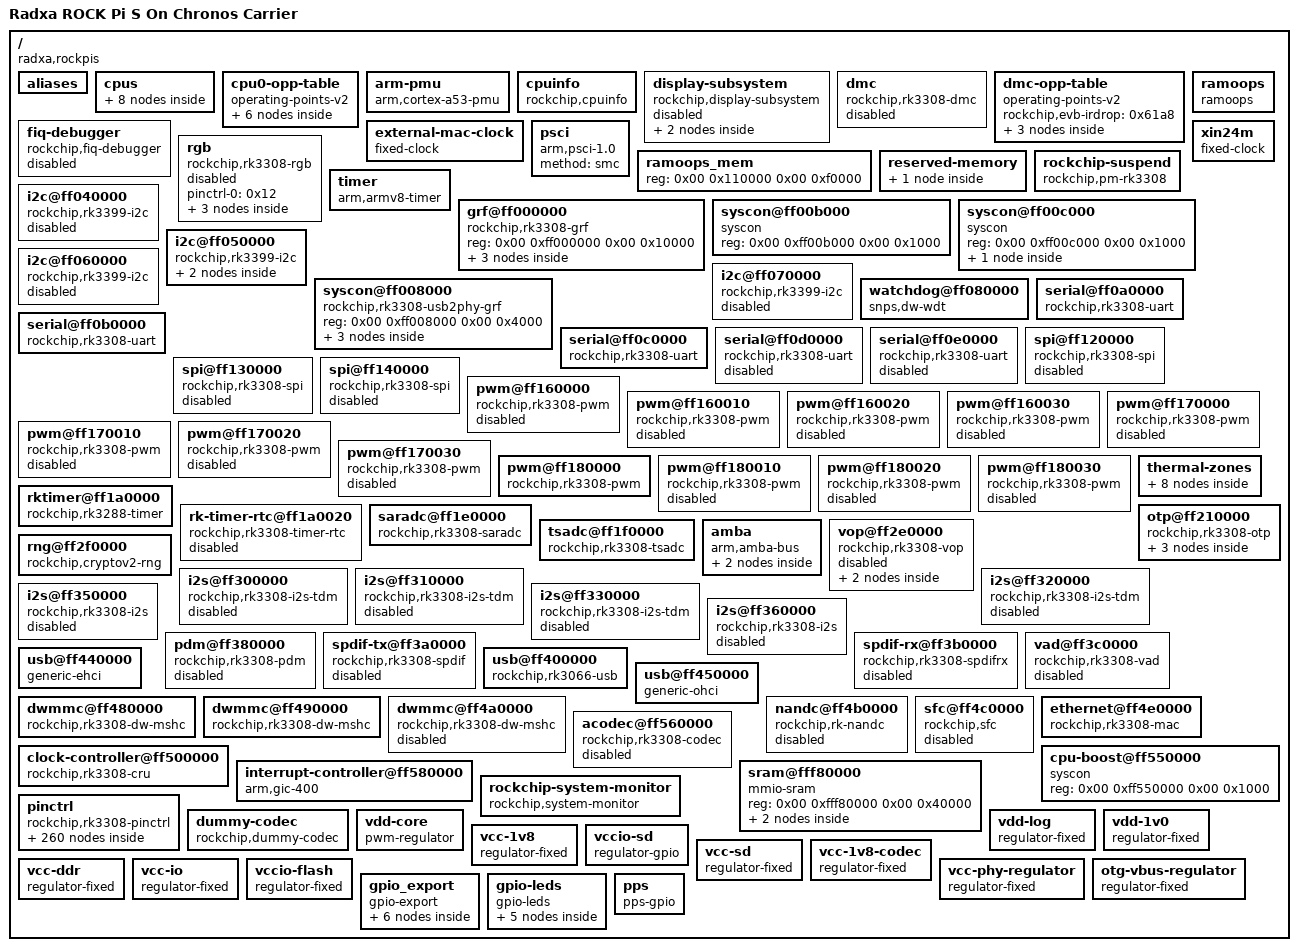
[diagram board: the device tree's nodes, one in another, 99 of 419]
/dts-v1/;

/ {
	compatible = "radxa,rockpis", "rockchip,rk3308";
	interrupt-parent = <0x01>;
	#address-cells = <0x02>;
	#size-cells = <0x02>;
	model = "Radxa ROCK Pi S On Chronos Carrier";

	aliases {
		ethernet0 = "/ethernet@ff4e0000";
		i2c0 = "/i2c@ff040000";
		i2c1 = "/i2c@ff050000";
		i2c2 = "/i2c@ff060000";
		i2c3 = "/i2c@ff070000";
		serial0 = "/serial@ff0a0000";
		serial1 = "/serial@ff0b0000";
		serial2 = "/serial@ff0c0000";
		serial3 = "/serial@ff0d0000";
		serial4 = "/serial@ff0e0000";
		spi0 = "/spi@ff120000";
		spi1 = "/spi@ff130000";
		spi2 = "/spi@ff140000";
	};

	cpus {
		#address-cells = <0x02>;
		#size-cells = <0x00>;

		cpu@0 {
			device_type = "cpu";
			compatible = "arm,cortex-a35", "arm,armv8";
			reg = <0x00 0x00>;
			enable-method = "psci";
			clocks = <0x02 0x05>;
			#cooling-cells = <0x02>;
			dynamic-power-coefficient = <0x53>;
			operating-points-v2 = <0x03>;
			cpu-idle-states = <0x04>;
			next-level-cache = <0x05>;
			cpu-supply = <0x06>;
			phandle = <0x08>;

			power-model {
				compatible = "simple-power-model";
				leakage-range = <0x05 0x32>;
				ls = <0x17c6 0x18ca 0xffffffc1>;
				static-coefficient = <0x186a0>;
				ts = <0xfffe55b6 0x18c54 0xfffff9ac 0x1e>;
				thermal-zone = "soc-thermal";
			};
		};

		cpu@1 {
			device_type = "cpu";
			compatible = "arm,cortex-a35", "arm,armv8";
			reg = <0x00 0x01>;
			enable-method = "psci";
			operating-points-v2 = <0x03>;
			cpu-idle-states = <0x04>;
			next-level-cache = <0x05>;
			phandle = <0x09>;
		};

		cpu@2 {
			device_type = "cpu";
			compatible = "arm,cortex-a35", "arm,armv8";
			reg = <0x00 0x02>;
			enable-method = "psci";
			operating-points-v2 = <0x03>;
			cpu-idle-states = <0x04>;
			next-level-cache = <0x05>;
			phandle = <0x0a>;
		};

		cpu@3 {
			device_type = "cpu";
			compatible = "arm,cortex-a35", "arm,armv8";
			reg = <0x00 0x03>;
			enable-method = "psci";
			operating-points-v2 = <0x03>;
			cpu-idle-states = <0x04>;
			next-level-cache = <0x05>;
			phandle = <0x0b>;
		};

		idle-states {
			entry-method = "psci";

			cpu-sleep {
				compatible = "arm,idle-state";
				local-timer-stop;
				arm,psci-suspend-param = <0x10000>;
				entry-latency-us = <0x78>;
				exit-latency-us = <0xfa>;
				min-residency-us = <0x384>;
				phandle = <0x04>;
			};
		};

		l2-cache {
			compatible = "cache";
			phandle = <0x05>;
		};
	};

	cpu0-opp-table {
		compatible = "operating-points-v2";
		opp-shared;
		rockchip,temp-hysteresis = <0x1388>;
		rockchip,low-temp = <0x00>;
		rockchip,low-temp-min-volt = <0xf4240>;
		rockchip,max-volt = <0x147260>;
		rockchip,low-temp-adjust-volt = <0x00 0x510 0xc350>;
		rockchip,evb-irdrop = <0x61a8>;
		nvmem-cells = <0x07>;
		nvmem-cell-names = "leakage";
		rockchip,pvtm-voltage-sel = <0x00 0xd2f0 0x00 0xd2f1 0xdac0 0x01 0xdac1 0xe484 0x02 0xe485 0xee48 0x03 0xee49 0xf80c 0x04 0xf80d 0x1869f 0x05>;
		rockchip,pvtm-freq = <0x639c0>;
		rockchip,pvtm-volt = <0xfa3e8>;
		rockchip,pvtm-ch = <0x00 0x00>;
		rockchip,pvtm-sample-time = <0x3e8>;
		rockchip,pvtm-number = <0x0a>;
		rockchip,pvtm-error = <0x3e8>;
		rockchip,pvtm-ref-temp = <0x23>;
		rockchip,pvtm-temp-prop = <0xfffffff1 0xffffffdb>;
		rockchip,thermal-zone = "soc-thermal";
		phandle = <0x03>;

		opp-408000000 {
			opp-hz = <0x00 0x18519600>;
			opp-microvolt = <0xe7ef0 0xe7ef0 0x147260>;
			clock-latency-ns = <0x9c40>;
			opp-suspend;
		};

		opp-600000000 {
			opp-hz = <0x00 0x23c34600>;
			opp-microvolt = <0xe7ef0 0xe7ef0 0x147260>;
			clock-latency-ns = <0x9c40>;
		};

		opp-816000000 {
			opp-hz = <0x00 0x30a32c00>;
			opp-microvolt = <0xfa3e8 0xfa3e8 0x147260>;
			opp-microvolt-L0 = <0xfa3e8 0xfa3e8 0x147260>;
			opp-microvolt-L1 = <0xfa3e8 0xfa3e8 0x147260>;
			opp-microvolt-L2 = <0xfa3e8 0xfa3e8 0x147260>;
			opp-microvolt-L3 = <0xf4240 0xf4240 0x147260>;
			opp-microvolt-L4 = <0xee098 0xee098 0x147260>;
			opp-microvolt-L5 = <0xe7ef0 0xe7ef0 0x147260>;
			clock-latency-ns = <0x9c40>;
		};

		opp-1008000000 {
			opp-hz = <0x00 0x3c14dc00>;
			opp-microvolt = <0x112a88 0x112a88 0x147260>;
			opp-microvolt-L0 = <0x112a88 0x112a88 0x147260>;
			opp-microvolt-L1 = <0x10c8e0 0x10c8e0 0x147260>;
			opp-microvolt-L2 = <0x10c8e0 0x10c8e0 0x147260>;
			opp-microvolt-L3 = <0x106738 0x106738 0x147260>;
			opp-microvolt-L4 = <0x100590 0x100590 0x147260>;
			opp-microvolt-L5 = <0xfa3e8 0xfa3e8 0x147260>;
			clock-latency-ns = <0x9c40>;
		};

		opp-1200000000 {
			opp-hz = <0x00 0x47868c00>;
			opp-microvolt = <0x1312d0 0x1312d0 0x147260>;
			opp-microvolt-L0 = <0x1312d0 0x1312d0 0x147260>;
			opp-microvolt-L1 = <0x12b128 0x12b128 0x147260>;
			opp-microvolt-L2 = <0x124f80 0x124f80 0x147260>;
			opp-microvolt-L3 = <0x11edd8 0x11edd8 0x147260>;
			opp-microvolt-L4 = <0x118c30 0x118c30 0x147260>;
			opp-microvolt-L5 = <0x112a88 0x112a88 0x147260>;
			clock-latency-ns = <0x9c40>;
		};

		opp-1296000000 {
			opp-hz = <0x00 0x4d3f6400>;
			opp-microvolt = <0x13d620 0x13d620 0x147260>;
			opp-microvolt-L0 = <0x13d620 0x13d620 0x147260>;
			opp-microvolt-L1 = <0x137478 0x137478 0x147260>;
			opp-microvolt-L2 = <0x1312d0 0x1312d0 0x147260>;
			opp-microvolt-L3 = <0x12b128 0x12b128 0x147260>;
			opp-microvolt-L4 = <0x124f80 0x124f80 0x147260>;
			opp-microvolt-L5 = <0x11edd8 0x11edd8 0x147260>;
			clock-latency-ns = <0x9c40>;
		};
	};

	arm-pmu {
		compatible = "arm,cortex-a53-pmu";
		interrupts = <0x00 0x53 0x04 0x00 0x54 0x04 0x00 0x55 0x04 0x00 0x56 0x04>;
		interrupt-affinity = <0x08 0x09 0x0a 0x0b>;
	};

	cpuinfo {
		compatible = "rockchip,cpuinfo";
		nvmem-cells = <0x0c>;
		nvmem-cell-names = "id";
	};

	display-subsystem {
		compatible = "rockchip,display-subsystem";
		ports = <0x0d>;
		logo-memory-region = <0x0e>;
		status = "disabled";
		phandle = <0x87>;

		route {

			route-rgb {
				status = "disabled";
				logo,uboot = "logo.bmp";
				logo,mode = "center";
				charge_logo,mode = "center";
				connect = <0x0f>;
				phandle = <0x88>;
			};
		};
	};

	dmc {
		compatible = "rockchip,rk3308-dmc";
		clocks = <0x02 0x46>;
		clock-names = "dmc_clk";
		operating-points-v2 = <0x10>;
		status = "disabled";
		phandle = <0x89>;
	};

	dmc-opp-table {
		compatible = "operating-points-v2";
		rockchip,evb-irdrop = <0x61a8>;
		phandle = <0x10>;

		opp-394000000 {
			opp-hz = <0x00 0x177bf680>;
			opp-microvolt = <0xe7ef0>;
		};

		opp-452000000 {
			opp-hz = <0x00 0x1af0f900>;
			opp-microvolt = <0xee098>;
		};

		opp-590000000 {
			opp-hz = <0x00 0x232aaf80>;
			opp-microvolt = <0xf4240>;
		};
	};

	fiq-debugger {
		compatible = "rockchip,fiq-debugger";
		rockchip,serial-id = <0x02>;
		rockchip,wake-irq = <0x00>;
		rockchip,irq-mode-enable = <0x00>;
		rockchip,baudrate = <0x16e360>;
		interrupts = <0x00 0x74 0x04>;
		status = "disabled";
		phandle = <0x8a>;
	};

	external-mac-clock {
		compatible = "fixed-clock";
		clock-frequency = <0x2faf080>;
		clock-output-names = "mac_clkin";
		#clock-cells = <0x00>;
		phandle = <0x8b>;
	};

	psci {
		compatible = "arm,psci-1.0";
		method = "smc";
	};

	ramoops_mem {
		reg = <0x00 0x110000 0x00 0xf0000>;
		reg-names = "ramoops_mem";
		phandle = <0x11>;
	};

	ramoops {
		compatible = "ramoops";
		record-size = <0x00 0x30000>;
		console-size = <0x00 0xc0000>;
		ftrace-size = <0x00 0x00>;
		pmsg-size = <0x00 0x00>;
		memory-region = <0x11>;
		phandle = <0x8c>;
	};

	rgb {
		compatible = "rockchip,rk3308-rgb";
		status = "disabled";
		pinctrl-names = "default";
		pinctrl-0 = <0x12>;
		phandle = <0x8d>;

		ports {
			#address-cells = <0x01>;
			#size-cells = <0x00>;

			port@0 {
				reg = <0x00>;
				#address-cells = <0x01>;
				#size-cells = <0x00>;

				endpoint@0 {
					reg = <0x00>;
					remote-endpoint = <0x0f>;
					phandle = <0x4d>;
				};
			};
		};
	};

	reserved-memory {
		#address-cells = <0x02>;
		#size-cells = <0x02>;
		ranges;

		drm-logo@00000000 {
			compatible = "rockchip,drm-logo";
			reg = <0x00 0x00 0x00 0x00>;
			phandle = <0x0e>;
		};
	};

	rockchip-suspend {
		compatible = "rockchip,pm-rk3308";
		status = "okay";
		rockchip,sleep-mode-config = <0x8000008>;
		rockchip,wakeup-config = <0x40000>;
		rockchip,pwm-regulator-config = <0x04>;
		phandle = <0x8e>;
	};

	timer {
		compatible = "arm,armv8-timer";
		interrupts = <0x01 0x0d 0xf04 0x01 0x0e 0xf04 0x01 0x0b 0xf04 0x01 0x0a 0xf04>;
	};

	xin24m {
		compatible = "fixed-clock";
		#clock-cells = <0x00>;
		clock-frequency = <0x16e3600>;
		clock-output-names = "xin24m";
		phandle = <0x8f>;
	};

	grf@ff000000 {
		compatible = "rockchip,rk3308-grf", "syscon", "simple-mfd";
		reg = <0x00 0xff000000 0x00 0x10000>;
		phandle = <0x4a>;

		io-domains {
			compatible = "rockchip,rk3308-io-voltage-domain";
			status = "okay";
			vccio0-supply = <0x13>;
			vccio1-supply = <0x13>;
			vccio2-supply = <0x14>;
			vccio3-supply = <0x15>;
			vccio4-supply = <0x14>;
			vccio5-supply = <0x13>;
			phandle = <0x90>;
		};

		pmu-pvtm {
			compatible = "rockchip,rk3308-pmu-pvtm";
			clocks = <0x02 0x4a>;
			clock-names = "pmu";
			phandle = <0x91>;
		};

		reboot-mode {
			compatible = "syscon-reboot-mode";
			offset = <0x500>;
			mode-bootloader = <0x5242c301>;
			mode-loader = <0x5242c301>;
			mode-normal = <0x5242c300>;
			mode-recovery = <0x5242c303>;
			mode-fastboot = <0x5242c309>;
			mode-panic = <0x5242c307>;
			mode-watchdog = <0x5242c308>;
		};
	};

	syscon@ff00b000 {
		compatible = "syscon", "simple-mfd";
		reg = <0x00 0xff00b000 0x00 0x1000>;
		#address-cells = <0x01>;
		#size-cells = <0x01>;
		phandle = <0x76>;
	};

	syscon@ff00c000 {
		compatible = "syscon", "simple-mfd";
		reg = <0x00 0xff00c000 0x00 0x1000>;
		#address-cells = <0x01>;
		#size-cells = <0x01>;
		phandle = <0x92>;

		pvtm {
			compatible = "rockchip,rk3308-pvtm";
			clocks = <0x02 0x10>;
			clock-names = "core";
			phandle = <0x93>;
		};
	};

	i2c@ff040000 {
		compatible = "rockchip,rk3399-i2c";
		reg = <0x00 0xff040000 0x00 0x1000>;
		clocks = <0x02 0x16 0x02 0xca>;
		clock-names = "i2c", "pclk";
		interrupts = <0x00 0x0b 0x04>;
		pinctrl-names = "default";
		pinctrl-0 = <0x16>;
		#address-cells = <0x01>;
		#size-cells = <0x00>;
		status = "disabled";
		phandle = <0x94>;
	};

	i2c@ff050000 {
		compatible = "rockchip,rk3399-i2c";
		reg = <0x00 0xff050000 0x00 0x1000>;
		clocks = <0x02 0x17 0x02 0xcb>;
		clock-names = "i2c", "pclk";
		interrupts = <0x00 0x0c 0x04>;
		pinctrl-names = "default";
		pinctrl-0 = <0x17>;
		#address-cells = <0x01>;
		#size-cells = <0x00>;
		status = "okay";
		clock-frequency = <0x61a80>;
		phandle = <0x95>;

		hym8563@51 {
			compatible = "haoyu,hym8563";
			reg = <0x51>;
			#clock-cells = <0x00>;
			clock-frequency = <0x8000>;
			clock-output-names = "xin32k";
			pinctrl-names = "default";
			pinctrl-0 = <0x18>;
			interrupt-parent = <0x19>;
			interrupts = <0x11 0x08>;
			status = "okay";
			phandle = <0x96>;
		};

		eeprom@54 {
			compatible = "st,24c64";
			reg = <0x54>;
			pagesize = <0x20>;
			phandle = <0x97>;
		};
	};

	i2c@ff060000 {
		compatible = "rockchip,rk3399-i2c";
		reg = <0x00 0xff060000 0x00 0x1000>;
		clocks = <0x02 0x18 0x02 0xcc>;
		clock-names = "i2c", "pclk";
		interrupts = <0x00 0x0d 0x04>;
		pinctrl-names = "default";
		pinctrl-0 = <0x1a>;
		#address-cells = <0x01>;
		#size-cells = <0x00>;
		status = "disabled";
		phandle = <0x98>;
	};

	i2c@ff070000 {
		compatible = "rockchip,rk3399-i2c";
		reg = <0x00 0xff070000 0x00 0x1000>;
		clocks = <0x02 0x19 0x02 0xcd>;
		clock-names = "i2c", "pclk";
		interrupts = <0x00 0x0e 0x04>;
		pinctrl-names = "default";
		pinctrl-0 = <0x1b>;
		#address-cells = <0x01>;
		#size-cells = <0x00>;
		status = "disabled";
		phandle = <0x99>;
	};

	syscon@ff008000 {
		compatible = "rockchip,rk3308-usb2phy-grf", "syscon", "simple-mfd";
		reg = <0x00 0xff008000 0x00 0x4000>;
		#address-cells = <0x01>;
		#size-cells = <0x01>;
		phandle = <0x9a>;

		usb2-phy@100 {
			compatible = "rockchip,rk3308-usb2phy";
			reg = <0x100 0x10>;
			clocks = <0x02 0x48>;
			clock-names = "phyclk";
			#clock-cells = <0x00>;
			assigned-clocks = <0x02 0x0e>;
			assigned-clock-parents = <0x1c>;
			clock-output-names = "usb480m_phy";
			status = "okay";
			phandle = <0x1c>;

			otg-port {
				#phy-cells = <0x00>;
				interrupts = <0x00 0x43 0x04 0x00 0x44 0x04 0x00 0x45 0x04>;
				interrupt-names = "otg-bvalid", "otg-id", "linestate";
				status = "okay";
				vbus-supply = <0x1d>;
				phandle = <0x67>;
			};

			host-port {
				#phy-cells = <0x00>;
				interrupts = <0x00 0x4a 0x04>;
				interrupt-names = "linestate";
				status = "okay";
				phy-supply = <0x1d>;
				phandle = <0x68>;
			};
		};
	};

	watchdog@ff080000 {
		compatible = "snps,dw-wdt";
		reg = <0x00 0xff080000 0x00 0x100>;
		clocks = <0x02 0xd6>;
		interrupts = <0x00 0x0a 0x04>;
		status = "okay";
		phandle = <0x9b>;
	};

	serial@ff0a0000 {
		compatible = "rockchip,rk3308-uart", "snps,dw-apb-uart";
		reg = <0x00 0xff0a0000 0x00 0x100>;
		interrupts = <0x00 0x12 0x04>;
		clocks = <0x02 0x11 0x02 0xc5>;
		clock-names = "baudclk", "apb_pclk";
		reg-shift = <0x02>;
		reg-io-width = <0x04>;
		dmas = <0x1e 0x04 0x1e 0x05>;
		dma-names = "tx", "rx";
		pinctrl-names = "default";
		pinctrl-0 = <0x1f>;
		status = "okay";
		phandle = <0x9c>;
	};

	serial@ff0b0000 {
		compatible = "rockchip,rk3308-uart", "snps,dw-apb-uart";
		reg = <0x00 0xff0b0000 0x00 0x100>;
		interrupts = <0x00 0x13 0x04>;
		clocks = <0x02 0x12 0x02 0xc6>;
		clock-names = "baudclk", "apb_pclk";
		reg-shift = <0x02>;
		reg-io-width = <0x04>;
		dmas = <0x1e 0x06 0x1e 0x07>;
		dma-names = "tx", "rx";
		pinctrl-names = "default";
		pinctrl-0 = <0x20>;
		status = "okay";
		phandle = <0x9d>;
	};

	serial@ff0c0000 {
		compatible = "rockchip,rk3308-uart", "snps,dw-apb-uart";
		reg = <0x00 0xff0c0000 0x00 0x100>;
		interrupts = <0x00 0x14 0x04>;
		clocks = <0x02 0x13 0x02 0xc7>;
		clock-names = "baudclk", "apb_pclk";
		reg-shift = <0x02>;
		reg-io-width = <0x04>;
		dmas = <0x1e 0x08 0x1e 0x09>;
		dma-names = "tx", "rx";
		pinctrl-names = "default";
		pinctrl-0 = <0x21>;
		status = "okay";
		phandle = <0x9e>;
	};

	serial@ff0d0000 {
		compatible = "rockchip,rk3308-uart", "snps,dw-apb-uart";
		reg = <0x00 0xff0d0000 0x00 0x100>;
		interrupts = <0x00 0x15 0x04>;
		clocks = <0x02 0x14 0x02 0xc8>;
		clock-names = "baudclk", "apb_pclk";
		reg-shift = <0x02>;
		reg-io-width = <0x04>;
		dmas = <0x1e 0x0a 0x1e 0x0b>;
		dma-names = "tx", "rx";
		pinctrl-names = "default";
		pinctrl-0 = <0x22>;
		status = "disabled";
		phandle = <0x9f>;
	};

	serial@ff0e0000 {
		compatible = "rockchip,rk3308-uart", "snps,dw-apb-uart";
		reg = <0x00 0xff0e0000 0x00 0x100>;
		interrupts = <0x00 0x16 0x04>;
		clocks = <0x02 0x15 0x02 0xc9>;
		clock-names = "baudclk", "apb_pclk";
		reg-shift = <0x02>;
		reg-io-width = <0x04>;
		dmas = <0x23 0x12 0x23 0x13>;
		dma-names = "tx", "rx";
		pinctrl-names = "default";
		pinctrl-0 = <0x24 0x25 0x26>;
		status = "disabled";
		phandle = <0xa0>;
	};

	spi@ff120000 {
		compatible = "rockchip,rk3308-spi", "rockchip,rk3066-spi";
		reg = <0x00 0xff120000 0x00 0x1000>;
		interrupts = <0x00 0x0f 0x04>;
		#address-cells = <0x01>;
		#size-cells = <0x00>;
		clocks = <0x02 0x1b 0x02 0xcf>;
		clock-names = "spiclk", "apb_pclk";
		dmas = <0x1e 0x00 0x1e 0x01>;
		dma-names = "tx", "rx";
		pinctrl-names = "default", "high_speed";
		pinctrl-0 = <0x27 0x28 0x29 0x2a>;
		pinctrl-1 = <0x2b 0x28 0x2c 0x2d>;
		status = "disabled";
		phandle = <0xa1>;
	};

	spi@ff130000 {
		compatible = "rockchip,rk3308-spi", "rockchip,rk3066-spi";
		reg = <0x00 0xff130000 0x00 0x1000>;
		interrupts = <0x00 0x10 0x04>;
		#address-cells = <0x01>;
		#size-cells = <0x00>;
		clocks = <0x02 0x1c 0x02 0xd0>;
		clock-names = "spiclk", "apb_pclk";
		dmas = <0x1e 0x02 0x1e 0x03>;
		dma-names = "tx", "rx";
		pinctrl-names = "default", "high_speed";
		pinctrl-0 = <0x2e 0x2f 0x30 0x31>;
		pinctrl-1 = <0x32 0x2f 0x33 0x34>;
		status = "disabled";
		phandle = <0xa2>;
	};

	spi@ff140000 {
		compatible = "rockchip,rk3308-spi", "rockchip,rk3066-spi";
		reg = <0x00 0xff140000 0x00 0x1000>;
		interrupts = <0x00 0x11 0x04>;
		#address-cells = <0x01>;
		#size-cells = <0x00>;
		clocks = <0x02 0x1d 0x02 0xd1>;
		clock-names = "spiclk", "apb_pclk";
		dmas = <0x23 0x10 0x23 0x11>;
		dma-names = "tx", "rx";
		pinctrl-names = "default", "high_speed";
		pinctrl-0 = <0x35 0x36 0x37 0x38>;
		pinctrl-1 = <0x39 0x36 0x3a 0x3b>;
		status = "disabled";
		phandle = <0xa3>;
	};

	pwm@ff160000 {
		compatible = "rockchip,rk3308-pwm", "rockchip,rk3328-pwm";
		reg = <0x00 0xff160000 0x00 0x10>;
		#pwm-cells = <0x03>;
		pinctrl-names = "active";
		pinctrl-0 = <0x3c>;
		clocks = <0x02 0x79 0x02 0xe8>;
		clock-names = "pwm", "pclk";
		status = "disabled";
		phandle = <0xa4>;
	};

	pwm@ff160010 {
		compatible = "rockchip,rk3308-pwm", "rockchip,rk3328-pwm";
		reg = <0x00 0xff160010 0x00 0x10>;
		#pwm-cells = <0x03>;
		pinctrl-names = "active";
		pinctrl-0 = <0x3d>;
		clocks = <0x02 0x79 0x02 0xe8>;
		clock-names = "pwm", "pclk";
		status = "disabled";
		phandle = <0xa5>;
	};

	pwm@ff160020 {
		compatible = "rockchip,rk3308-pwm", "rockchip,rk3328-pwm";
		reg = <0x00 0xff160020 0x00 0x10>;
		#pwm-cells = <0x03>;
		pinctrl-names = "active";
		pinctrl-0 = <0x3e>;
		clocks = <0x02 0x79 0x02 0xe8>;
		clock-names = "pwm", "pclk";
		status = "disabled";
		phandle = <0xa6>;
	};

	pwm@ff160030 {
		compatible = "rockchip,rk3308-pwm", "rockchip,rk3328-pwm";
		reg = <0x00 0xff160030 0x00 0x10>;
		#pwm-cells = <0x03>;
		pinctrl-names = "active";
		pinctrl-0 = <0x3f>;
		clocks = <0x02 0x79 0x02 0xe8>;
		clock-names = "pwm", "pclk";
		status = "disabled";
		phandle = <0xa7>;
	};

	pwm@ff170000 {
		compatible = "rockchip,rk3308-pwm", "rockchip,rk3328-pwm";
		reg = <0x00 0xff170000 0x00 0x10>;
		#pwm-cells = <0x03>;
		pinctrl-names = "active";
		pinctrl-0 = <0x40>;
		clocks = <0x02 0x78 0x02 0xe7>;
		clock-names = "pwm", "pclk";
		status = "disabled";
		phandle = <0xa8>;
	};

	pwm@ff170010 {
		compatible = "rockchip,rk3308-pwm", "rockchip,rk3328-pwm";
		reg = <0x00 0xff170010 0x00 0x10>;
		#pwm-cells = <0x03>;
		pinctrl-names = "active";
		pinctrl-0 = <0x41>;
		clocks = <0x02 0x78 0x02 0xe7>;
		clock-names = "pwm", "pclk";
		status = "disabled";
		phandle = <0xa9>;
	};

	pwm@ff170020 {
		compatible = "rockchip,rk3308-pwm", "rockchip,rk3328-pwm";
		reg = <0x00 0xff170020 0x00 0x10>;
		#pwm-cells = <0x03>;
		pinctrl-names = "active";
		pinctrl-0 = <0x42>;
		clocks = <0x02 0x78 0x02 0xe7>;
		clock-names = "pwm", "pclk";
		status = "disabled";
		phandle = <0xaa>;
	};

	pwm@ff170030 {
		compatible = "rockchip,rk3308-pwm", "rockchip,rk3328-pwm";
		reg = <0x00 0xff170030 0x00 0x10>;
		#pwm-cells = <0x03>;
		pinctrl-names = "active";
		pinctrl-0 = <0x43>;
		clocks = <0x02 0x78 0x02 0xe7>;
		clock-names = "pwm", "pclk";
		status = "disabled";
		phandle = <0xab>;
	};

	pwm@ff180000 {
		compatible = "rockchip,rk3308-pwm", "rockchip,rk3328-pwm";
		reg = <0x00 0xff180000 0x00 0x10>;
		#pwm-cells = <0x03>;
		pinctrl-names = "active";
		pinctrl-0 = <0x44>;
		clocks = <0x02 0x1a 0x02 0xce>;
		clock-names = "pwm", "pclk";
		status = "okay";
		phandle = <0x82>;
	};

	pwm@ff180010 {
		compatible = "rockchip,rk3308-pwm", "rockchip,rk3328-pwm";
		reg = <0x00 0xff180010 0x00 0x10>;
		#pwm-cells = <0x03>;
		pinctrl-names = "active";
		pinctrl-0 = <0x45>;
		clocks = <0x02 0x1a 0x02 0xce>;
		clock-names = "pwm", "pclk";
		status = "disabled";
		phandle = <0xac>;
	};

	pwm@ff180020 {
		compatible = "rockchip,rk3308-pwm", "rockchip,rk3328-pwm";
		reg = <0x00 0xff180020 0x00 0x10>;
		#pwm-cells = <0x03>;
		pinctrl-names = "active";
		pinctrl-0 = <0x46>;
		clocks = <0x02 0x1a 0x02 0xce>;
		clock-names = "pwm", "pclk";
		status = "disabled";
		phandle = <0xad>;
	};

	pwm@ff180030 {
		compatible = "rockchip,rk3308-pwm", "rockchip,rk3328-pwm";
		reg = <0x00 0xff180030 0x00 0x10>;
		#pwm-cells = <0x03>;
		pinctrl-names = "active";
		pinctrl-0 = <0x47>;
		clocks = <0x02 0x1a 0x02 0xce>;
		clock-names = "pwm", "pclk";
		status = "disabled";
		phandle = <0xae>;
	};

	rktimer@ff1a0000 {
		compatible = "rockchip,rk3288-timer";
		reg = <0x00 0xff1a0000 0x00 0x20>;
		interrupts = <0x00 0x19 0x04>;
		clocks = <0x02 0xd4 0x02 0x1e>;
		clock-names = "pclk", "timer";
		phandle = <0xaf>;
	};

	rk-timer-rtc@ff1a0020 {
		compatible = "rockchip,rk3308-timer-rtc";
		reg = <0x00 0xff1a0020 0x00 0x20>;
		interrupts = <0x00 0x1a 0x04>;
		clocks = <0x02 0xd4 0x02 0x1f>;
		clock-names = "pclk", "timer";
		status = "disabled";
		phandle = <0xb0>;
	};

	saradc@ff1e0000 {
		compatible = "rockchip,rk3308-saradc", "rockchip,rk3399-saradc";
		reg = <0x00 0xff1e0000 0x00 0x100>;
		interrupts = <0x00 0x25 0x04>;
		#io-channel-cells = <0x01>;
		clocks = <0x02 0x25 0x02 0xd2>;
		clock-names = "saradc", "apb_pclk";
		resets = <0x02 0x46>;
		reset-names = "saradc-apb";
		status = "okay";
		phandle = <0xb1>;
	};

	thermal-zones {
		phandle = <0xb2>;

		soc-thermal {
			polling-delay-passive = <0x14>;
			polling-delay = <0x3e8>;
			sustainable-power = <0x168>;
			thermal-sensors = <0x48 0x01>;
			phandle = <0xb3>;

			trips {

				trip-point-0 {
					temperature = <0x11170>;
					hysteresis = <0x7d0>;
					type = "passive";
					phandle = <0xb4>;
				};

				trip-point-1 {
					temperature = <0x14c08>;
					hysteresis = <0x7d0>;
					type = "passive";
					phandle = <0x49>;
				};

				soc-crit {
					temperature = <0x1c138>;
					hysteresis = <0x7d0>;
					type = "critical";
					phandle = <0xb5>;
				};
			};

			cooling-maps {

				map0 {
					trip = <0x49>;
					cooling-device = <0x08 0xffffffff 0xffffffff>;
					contribution = <0x1000>;
				};
			};
		};

		logic-thermal {
			polling-delay-passive = <0x64>;
			polling-delay = <0x3e8>;
			thermal-sensors = <0x48 0x00>;
			phandle = <0xb6>;
		};
	};

	tsadc@ff1f0000 {
		compatible = "rockchip,rk3308-tsadc";
		reg = <0x00 0xff1f0000 0x00 0x100>;
		interrupts = <0x00 0x26 0x04>;
		rockchip,grf = <0x4a>;
		clocks = <0x02 0x24 0x02 0xd3>;
		clock-names = "tsadc", "apb_pclk";
		assigned-clocks = <0x02 0x24>;
		assigned-clock-rates = <0xc350>;
		resets = <0x02 0x48>;
		reset-names = "tsadc-apb";
		pinctrl-names = "gpio", "otpout";
		pinctrl-0 = <0x4b>;
		pinctrl-1 = <0x4c>;
		#thermal-sensor-cells = <0x01>;
		rockchip,hw-tshut-temp = <0x1d4c0>;
		status = "okay";
		rockchip,hw-tshut-mode = <0x00>;
		rockchip,hw-tshut-polarity = <0x01>;
		phandle = <0x48>;
	};

	otp@ff210000 {
		compatible = "rockchip,rk3308-otp";
		reg = <0x00 0xff210000 0x00 0x4000>;
		#address-cells = <0x01>;
		#size-cells = <0x01>;
		clocks = <0x02 0x27 0x02 0xd5 0x02 0xe5>;
		clock-names = "clk_otp", "pclk_otp", "pclk_otp_phy";
		resets = <0x02 0x54>;
		reset-names = "otp_phy";
		phandle = <0xb7>;

		id@7 {
			reg = <0x07 0x10>;
			phandle = <0x0c>;
		};

		cpu-leakage@17 {
			reg = <0x17 0x01>;
			phandle = <0x07>;
		};

		logic-leakage@18 {
			reg = <0x18 0x01>;
			phandle = <0xb8>;
		};
	};

	amba {
		compatible = "arm,amba-bus";
		#address-cells = <0x02>;
		#size-cells = <0x02>;
		ranges;

		dma-controller@ff2c0000 {
			compatible = "arm,pl330", "arm,primecell";
			reg = <0x00 0xff2c0000 0x00 0x4000>;
			interrupts = <0x00 0x00 0x04 0x00 0x01 0x04>;
			#dma-cells = <0x01>;
			clocks = <0x02 0x8a>;
			clock-names = "apb_pclk";
			peripherals-req-type-burst;
			phandle = <0x1e>;
		};

		dma-controller@ff2d0000 {
			compatible = "arm,pl330", "arm,primecell";
			reg = <0x00 0xff2d0000 0x00 0x4000>;
			interrupts = <0x00 0x02 0x04 0x00 0x03 0x04>;
			#dma-cells = <0x01>;
			clocks = <0x02 0x8b>;
			clock-names = "apb_pclk";
			peripherals-req-type-burst;
			phandle = <0x23>;
		};
	};

	vop@ff2e0000 {
		compatible = "rockchip,rk3308-vop";
		reg = <0x00 0xff2e0000 0x00 0x1fc 0x00 0xff2e0a00 0x00 0x400>;
		reg-names = "regs", "gamma_lut";
		interrupts = <0x00 0x2e 0x04>;
		clocks = <0x02 0x88 0x02 0x7d 0x02 0xac>;
		clock-names = "aclk_vop", "dclk_vop", "hclk_vop";
		status = "disabled";
		phandle = <0xb9>;

		port {
			#address-cells = <0x01>;
			#size-cells = <0x00>;
			phandle = <0x0d>;

			endpoint@0 {
				reg = <0x00>;
				remote-endpoint = <0x4d>;
				phandle = <0x0f>;
			};
		};
	};

	rng@ff2f0000 {
		compatible = "rockchip,cryptov2-rng";
		reg = <0x00 0xff2f0000 0x00 0x4000>;
		clocks = <0x02 0x29 0x02 0x2a 0x02 0x87 0x02 0xab>;
		clock-names = "clk_crypto", "clk_crypto_apk", "aclk_crypto", "hclk_crypto";
		assigned-clocks = <0x02 0x29 0x02 0x2a 0x02 0x87 0x02 0xab>;
		assigned-clock-rates = <0x8f0d180 0x8f0d180 0xbebc200 0x5f5e100>;
		resets = <0x02 0x24>;
		reset-names = "reset";
		status = "okay";
		phandle = <0xba>;
	};

	i2s@ff300000 {
		compatible = "rockchip,rk3308-i2s-tdm";
		reg = <0x00 0xff300000 0x00 0x1000>;
		interrupts = <0x00 0x30 0x04>;
		clocks = <0x02 0x4c 0x02 0x4e 0x02 0xa4 0x02 0x6e 0x02 0x6f 0x02 0x03 0x02 0x04>;
		clock-names = "mclk_tx", "mclk_rx", "hclk", "mclk_tx_src", "mclk_rx_src", "mclk_root0", "mclk_root1";
		dmas = <0x23 0x00 0x23 0x01>;
		dma-names = "tx", "rx";
		resets = <0x02 0x89 0x02 0x8a>;
		reset-names = "tx-m", "rx-m";
		rockchip,cru = <0x02>;
		rockchip,grf = <0x4a>;
		rockchip,mclk-calibrate;
		pinctrl-names = "default";
		pinctrl-0 = <0x4e 0x4f 0x50 0x51 0x52 0x53 0x54 0x55 0x56 0x57 0x58 0x59 0x5a>;
		status = "disabled";
		phandle = <0xbb>;
	};

	i2s@ff310000 {
		compatible = "rockchip,rk3308-i2s-tdm";
		reg = <0x00 0xff310000 0x00 0x1000>;
		interrupts = <0x00 0x31 0x04>;
		clocks = <0x02 0x50 0x02 0x52 0x02 0xa5 0x02 0x70 0x02 0x71 0x02 0x03 0x02 0x04>;
		clock-names = "mclk_tx", "mclk_rx", "hclk", "mclk_tx_src", "mclk_rx_src", "mclk_root0", "mclk_root1";
		dmas = <0x23 0x02 0x23 0x03>;
		dma-names = "tx", "rx";
		resets = <0x02 0x8c 0x02 0x8d>;
		reset-names = "tx-m", "rx-m";
		rockchip,cru = <0x02>;
		rockchip,grf = <0x4a>;
		rockchip,mclk-calibrate;
		rockchip,io-multiplex;
		status = "disabled";
		phandle = <0xbc>;
	};

	i2s@ff320000 {
		compatible = "rockchip,rk3308-i2s-tdm";
		reg = <0x00 0xff320000 0x00 0x1000>;
		interrupts = <0x00 0x32 0x04>;
		clocks = <0x02 0x54 0x02 0x56 0x02 0xa6 0x02 0x72 0x02 0x73 0x02 0x03 0x02 0x04>;
		clock-names = "mclk_tx", "mclk_rx", "hclk", "mclk_tx_src", "mclk_rx_src", "mclk_root0", "mclk_root1";
		dmas = <0x23 0x04 0x23 0x05>;
		dma-names = "tx", "rx";
		resets = <0x02 0x8f 0x02 0x90>;
		reset-names = "tx-m", "rx-m";
		rockchip,cru = <0x02>;
		rockchip,grf = <0x4a>;
		rockchip,mclk-calibrate;
		status = "disabled";
		phandle = <0xbd>;
	};

	i2s@ff330000 {
		compatible = "rockchip,rk3308-i2s-tdm";
		reg = <0x00 0xff330000 0x00 0x1000>;
		interrupts = <0x00 0x33 0x04>;
		clocks = <0x02 0x58 0x02 0x5a 0x02 0xa7 0x02 0x74 0x02 0x75 0x02 0x03 0x02 0x04>;
		clock-names = "mclk_tx", "mclk_rx", "hclk", "mclk_tx_src", "mclk_rx_src", "mclk_root0", "mclk_root1";
		dmas = <0x23 0x07>;
		dma-names = "rx";
		resets = <0x02 0x92 0x02 0x93>;
		reset-names = "tx-m", "rx-m";
		rockchip,cru = <0x02>;
		rockchip,grf = <0x4a>;
		rockchip,mclk-calibrate;
		status = "disabled";
		phandle = <0xbe>;
	};

	i2s@ff350000 {
		compatible = "rockchip,rk3308-i2s", "rockchip,rk3066-i2s";
		reg = <0x00 0xff350000 0x00 0x1000>;
		interrupts = <0x00 0x34 0x04>;
		clocks = <0x02 0x5c 0x02 0xa8>;
		clock-names = "i2s_clk", "i2s_hclk";
		dmas = <0x23 0x08 0x23 0x09>;
		dma-names = "tx", "rx";
		resets = <0x02 0x95 0x02 0x94>;
		reset-names = "reset-m", "reset-h";
		pinctrl-names = "default";
		pinctrl-0 = <0x5b 0x5c 0x5d 0x5e>;
		status = "disabled";
		phandle = <0xbf>;
	};

	i2s@ff360000 {
		compatible = "rockchip,rk3308-i2s", "rockchip,rk3066-i2s";
		reg = <0x00 0xff360000 0x00 0x1000>;
		interrupts = <0x00 0x35 0x04>;
		clocks = <0x02 0x5e 0x02 0xa9>;
		clock-names = "i2s_clk", "i2s_hclk";
		dmas = <0x23 0x0b>;
		dma-names = "rx";
		resets = <0x02 0x97 0x02 0x96>;
		reset-names = "reset-m", "reset-h";
		status = "disabled";
		phandle = <0xc0>;
	};

	pdm@ff380000 {
		compatible = "rockchip,rk3308-pdm", "rockchip,pdm";
		reg = <0x00 0xff380000 0x00 0x1000>;
		clocks = <0x02 0x4b 0x02 0xa1>;
		clock-names = "pdm_clk", "pdm_hclk";
		dmas = <0x23 0x0c>;
		dma-names = "rx";
		resets = <0x02 0x83>;
		reset-names = "pdm-m";
		pinctrl-names = "default";
		pinctrl-0 = <0x5f 0x60 0x61 0x62 0x63>;
		status = "disabled";
		phandle = <0xc1>;
	};

	spdif-tx@ff3a0000 {
		compatible = "rockchip,rk3308-spdif", "rockchip,rk3328-spdif";
		reg = <0x00 0xff3a0000 0x00 0x1000>;
		interrupts = <0x00 0x37 0x04>;
		clocks = <0x02 0x62 0x02 0xa2>;
		clock-names = "mclk", "hclk";
		dmas = <0x23 0x0d>;
		dma-names = "tx";
		pinctrl-names = "default";
		pinctrl-0 = <0x64>;
		status = "disabled";
		phandle = <0xc2>;
	};

	spdif-rx@ff3b0000 {
		compatible = "rockchip,rk3308-spdifrx";
		reg = <0x00 0xff3b0000 0x00 0x1000>;
		interrupts = <0x00 0x38 0x04>;
		clocks = <0x02 0x65 0x02 0xa3>;
		clock-names = "mclk", "hclk";
		dmas = <0x23 0x0e>;
		dma-names = "rx";
		resets = <0x02 0x87>;
		reset-names = "spdifrx-m";
		pinctrl-names = "default";
		pinctrl-0 = <0x65>;
		status = "disabled";
		phandle = <0xc3>;
	};

	vad@ff3c0000 {
		compatible = "rockchip,rk3308-vad";
		reg = <0x00 0xff3c0000 0x00 0x10000>;
		reg-names = "vad";
		clocks = <0x02 0xaa>;
		clock-names = "hclk";
		interrupts = <0x00 0x39 0x04>;
		rockchip,audio-sram = <0x66>;
		rockchip,audio-src = <0x00>;
		rockchip,det-channel = <0x00>;
		rockchip,mode = <0x00>;
		status = "disabled";
		phandle = <0xc4>;
	};

	usb@ff400000 {
		compatible = "rockchip,rk3066-usb", "snps,dwc2";
		reg = <0x00 0xff400000 0x00 0x40000>;
		interrupts = <0x00 0x42 0x04>;
		clocks = <0x02 0x9e>;
		clock-names = "otg";
		dr_mode = "otg";
		g-np-tx-fifo-size = <0x10>;
		g-rx-fifo-size = <0x118>;
		g-tx-fifo-size = <0x100 0x80 0x80 0x40 0x20 0x10>;
		g-use-dma;
		phys = <0x67>;
		phy-names = "usb2-phy";
		status = "okay";
		phandle = <0xc5>;
	};

	usb@ff440000 {
		compatible = "generic-ehci";
		reg = <0x00 0xff440000 0x00 0x10000>;
		interrupts = <0x00 0x47 0x04>;
		clocks = <0x02 0x9f 0x02 0xa0 0x1c>;
		clock-names = "usbhost", "arbiter", "utmi";
		phys = <0x68>;
		phy-names = "usb";
		status = "okay";
		phandle = <0xc6>;
	};

	usb@ff450000 {
		compatible = "generic-ohci";
		reg = <0x00 0xff450000 0x00 0x10000>;
		interrupts = <0x00 0x48 0x04>;
		clocks = <0x02 0x9f 0x02 0xa0 0x1c>;
		clock-names = "usbhost", "arbiter", "utmi";
		phys = <0x68>;
		phy-names = "usb";
		status = "okay";
		phandle = <0xc7>;
	};

	dwmmc@ff480000 {
		compatible = "rockchip,rk3308-dw-mshc", "rockchip,rk3288-dw-mshc";
		reg = <0x00 0xff480000 0x00 0x4000>;
		max-frequency = <0x8f0d180>;
		bus-width = <0x04>;
		clocks = <0x02 0x9a 0x02 0x30 0x02 0x31 0x02 0x32>;
		clock-names = "biu", "ciu", "ciu-drv", "ciu-sample";
		fifo-depth = <0x100>;
		interrupts = <0x00 0x4c 0x04>;
		pinctrl-names = "default";
		pinctrl-0 = <0x69 0x6a 0x6b 0x6c>;
		status = "okay";
		max-frequeency = <0x8f0d180>;
		supports-sd;
		cap-mmc-highspeed;
		cap-sd-highspeed;
		disable-wp;
		num-slots = <0x01>;
		vmmc-supply = <0x6d>;
		vqmmc-supply = <0x6e>;
		ard-detect-delay = <0x320>;
		phandle = <0xc8>;
	};

	dwmmc@ff490000 {
		compatible = "rockchip,rk3308-dw-mshc", "rockchip,rk3288-dw-mshc";
		reg = <0x00 0xff490000 0x00 0x4000>;
		max-frequency = <0x8f0d180>;
		bus-width = <0x04>;
		clocks = <0x02 0x9c 0x02 0x3a 0x02 0x3b 0x02 0x3c>;
		clock-names = "biu", "ciu", "ciu-drv", "ciu-sample";
		fifo-depth = <0x100>;
		interrupts = <0x00 0x4d 0x04>;
		status = "okay";
		cap-mmc-highspeed;
		supports-sd;
		disable-wp;
		non-removable;
		num-slots = <0x01>;
		phandle = <0xc9>;
	};

	dwmmc@ff4a0000 {
		compatible = "rockchip,rk3308-dw-mshc", "rockchip,rk3288-dw-mshc";
		reg = <0x00 0xff4a0000 0x00 0x4000>;
		max-frequency = <0x8f0d180>;
		bus-width = <0x04>;
		clocks = <0x02 0x9b 0x02 0x35 0x02 0x36 0x02 0x37>;
		clock-names = "biu", "ciu", "ciu-drv", "ciu-sample";
		fifo-depth = <0x100>;
		interrupts = <0x00 0x4e 0x04>;
		pinctrl-names = "default";
		pinctrl-0 = <0x6f 0x70 0x71>;
		status = "disabled";
		phandle = <0xca>;
	};

	nandc@ff4b0000 {
		compatible = "rockchip,rk-nandc";
		reg = <0x00 0xff4b0000 0x00 0x4000>;
		interrupts = <0x00 0x51 0x04>;
		nandc_id = <0x00>;
		clocks = <0x02 0x2d 0x02 0x99>;
		clock-names = "clk_nandc", "hclk_nandc";
		status = "disabled";
		phandle = <0xcb>;
	};

	sfc@ff4c0000 {
		compatible = "rockchip,sfc";
		reg = <0x00 0xff4c0000 0x00 0x4000>;
		interrupts = <0x00 0x52 0x04>;
		clocks = <0x02 0x3d 0x02 0x9d>;
		clock-names = "clk_sfc", "hclk_sfc";
		assigned-clocks = <0x02 0x3d>;
		assigned-clock-rates = <0x5f5e100>;
		status = "disabled";
		phandle = <0xcc>;
	};

	ethernet@ff4e0000 {
		compatible = "rockchip,rk3308-mac";
		reg = <0x00 0xff4e0000 0x00 0x10000>;
		rockchip,grf = <0x4a>;
		interrupts = <0x00 0x40 0x04>;
		interrupt-names = "macirq";
		clocks = <0x02 0x40 0x02 0x42 0x02 0x42 0x02 0x41 0x02 0x40 0x02 0x86 0x02 0xc3 0x02 0x43>;
		clock-names = "stmmaceth", "mac_clk_rx", "mac_clk_tx", "clk_mac_ref", "clk_mac_refout", "aclk_mac", "pclk_mac", "clk_mac_speed";
		phy-mode = "rmii";
		pinctrl-names = "default";
		pinctrl-0 = <0x72 0x73>;
		resets = <0x02 0x7d>;
		reset-names = "stmmaceth";
		status = "okay";
		phy-supply = <0x74>;
		clock_in_out = "output";
		assigned-clocks = <0x02 0x40>;
		assigned-clock-parents = <0x02 0x3f>;
		snps,reset-gpio = <0x19 0x07 0x01>;
		snps,reset-active-low;
		snps,reset-delays-us = <0x00 0xc350 0xc350>;
		phandle = <0xcd>;
	};

	clock-controller@ff500000 {
		compatible = "rockchip,rk3308-cru";
		reg = <0x00 0xff500000 0x00 0x1000>;
		rockchip,grf = <0x4a>;
		rockchip,boost = <0x75>;
		#clock-cells = <0x01>;
		#reset-cells = <0x01>;
		assigned-clocks = <0x02 0x0f>;
		assigned-clock-rates = <0x8000>;
		phandle = <0x02>;
	};

	cpu-boost@ff550000 {
		compatible = "syscon";
		reg = <0x00 0xff550000 0x00 0x1000>;
		phandle = <0x75>;
	};

	acodec@ff560000 {
		compatible = "rockchip,rk3308-codec";
		reg = <0x00 0xff560000 0x00 0x10000>;
		rockchip,grf = <0x4a>;
		rockchip,detect-grf = <0x76>;
		interrupts = <0x00 0x72 0x04 0x00 0x73 0x04>;
		clocks = <0x02 0xc4 0x02 0x55 0x02 0x57>;
		clock-names = "acodec", "mclk_tx", "mclk_rx";
		resets = <0x02 0x99>;
		reset-names = "acodec-reset";
		status = "disabled";
		phandle = <0xce>;
	};

	interrupt-controller@ff580000 {
		compatible = "arm,gic-400";
		#interrupt-cells = <0x03>;
		#address-cells = <0x00>;
		interrupt-controller;
		reg = <0x00 0xff581000 0x00 0x1000 0x00 0xff582000 0x00 0x2000 0x00 0xff584000 0x00 0x2000 0x00 0xff586000 0x00 0x2000>;
		interrupts = <0x01 0x09 0x04>;
		phandle = <0x01>;
	};

	sram@fff80000 {
		compatible = "mmio-sram";
		reg = <0x00 0xfff80000 0x00 0x40000>;
		#address-cells = <0x01>;
		#size-cells = <0x01>;
		ranges = <0x00 0x00 0xfff80000 0x40000>;
		phandle = <0xcf>;

		ddr-sram@0 {
			reg = <0x00 0x8000>;
		};

		vad-sram@8000 {
			reg = <0x8000 0x38000>;
			phandle = <0x66>;
		};
	};

	rockchip-system-monitor {
		compatible = "rockchip,system-monitor";
		rockchip,thermal-zone = "soc-thermal";
		rockchip,polling-delay = <0xc8>;
		phandle = <0xd0>;
	};

	pinctrl {
		compatible = "rockchip,rk3308-pinctrl";
		rockchip,grf = <0x4a>;
		#address-cells = <0x02>;
		#size-cells = <0x02>;
		ranges;
		pinctrl-names = "default";
		pinctrl-0 = <0x77>;
		phandle = <0xd1>;

		gpio0@ff220000 {
			compatible = "rockchip,gpio-bank";
			reg = <0x00 0xff220000 0x00 0x100>;
			interrupts = <0x00 0x28 0x04>;
			clocks = <0x02 0xd7>;
			gpio-controller;
			#gpio-cells = <0x02>;
			interrupt-controller;
			#interrupt-cells = <0x02>;
			phandle = <0x19>;
		};

		gpio1@ff230000 {
			compatible = "rockchip,gpio-bank";
			reg = <0x00 0xff230000 0x00 0x100>;
			interrupts = <0x00 0x29 0x04>;
			clocks = <0x02 0xd8>;
			gpio-controller;
			#gpio-cells = <0x02>;
			interrupt-controller;
			#interrupt-cells = <0x02>;
			phandle = <0xd2>;
		};

		gpio2@ff240000 {
			compatible = "rockchip,gpio-bank";
			reg = <0x00 0xff240000 0x00 0x100>;
			interrupts = <0x00 0x2a 0x04>;
			clocks = <0x02 0xd9>;
			gpio-controller;
			#gpio-cells = <0x02>;
			interrupt-controller;
			#interrupt-cells = <0x02>;
			phandle = <0x85>;
		};

		gpio3@ff250000 {
			compatible = "rockchip,gpio-bank";
			reg = <0x00 0xff250000 0x00 0x100>;
			interrupts = <0x00 0x2b 0x04>;
			clocks = <0x02 0xda>;
			gpio-controller;
			#gpio-cells = <0x02>;
			interrupt-controller;
			#interrupt-cells = <0x02>;
			phandle = <0xd3>;
		};

		gpio4@ff260000 {
			compatible = "rockchip,gpio-bank";
			reg = <0x00 0xff260000 0x00 0x100>;
			interrupts = <0x00 0x2c 0x04>;
			clocks = <0x02 0xdb>;
			gpio-controller;
			#gpio-cells = <0x02>;
			interrupt-controller;
			#interrupt-cells = <0x02>;
			phandle = <0x83>;
		};

		pcfg-pull-up {
			bias-pull-up;
			phandle = <0x7c>;
		};

		pcfg-pull-down {
			bias-pull-down;
			phandle = <0x78>;
		};

		pcfg-pull-none {
			bias-disable;
			phandle = <0x7a>;
		};

		pcfg-pull-none-2ma {
			bias-disable;
			drive-strength = <0x02>;
			phandle = <0xd4>;
		};

		pcfg-pull-up-2ma {
			bias-pull-up;
			drive-strength = <0x02>;
			phandle = <0xd5>;
		};

		pcfg-pull-up-4ma {
			bias-pull-up;
			drive-strength = <0x04>;
			phandle = <0x7d>;
		};

		pcfg-pull-none-4ma {
			bias-disable;
			drive-strength = <0x04>;
			phandle = <0x7b>;
		};

		pcfg-pull-down-4ma {
			bias-pull-down;
			drive-strength = <0x04>;
			phandle = <0xd6>;
		};

		pcfg-pull-none-8ma {
			bias-disable;
			drive-strength = <0x08>;
			phandle = <0x7f>;
		};

		pcfg-pull-up-8ma {
			bias-pull-up;
			drive-strength = <0x08>;
			phandle = <0x7e>;
		};

		pcfg-pull-none-12ma {
			bias-disable;
			drive-strength = <0x0c>;
			phandle = <0x81>;
		};

		pcfg-pull-up-12ma {
			bias-pull-up;
			drive-strength = <0x0c>;
			phandle = <0x80>;
		};

		pcfg-pull-none-smt {
			bias-disable;
			input-schmitt-enable;
			phandle = <0x79>;
		};

		pcfg-output-high {
			output-high;
			phandle = <0xd7>;
		};

		pcfg-output-low {
			output-low;
			phandle = <0xd8>;
		};

		pcfg-input-high {
			bias-pull-up;
			input-enable;
			phandle = <0xd9>;
		};

		pcfg-input {
			input-enable;
			phandle = <0xda>;
		};

		ext_micbias {

			ext-micbias-en {
				rockchip,pins = <0x00 0x12 0x00 0x78>;
				phandle = <0xdb>;
			};
		};

		i2c0 {

			i2c0-xfer {
				rockchip,pins = <0x01 0x18 0x02 0x79 0x01 0x19 0x02 0x79>;
				phandle = <0x16>;
			};
		};

		i2c1 {

			i2c1-xfer {
				rockchip,pins = <0x00 0x0b 0x01 0x79 0x00 0x0c 0x01 0x79>;
				phandle = <0x17>;
			};
		};

		i2c2 {

			i2c2-xfer {
				rockchip,pins = <0x02 0x02 0x03 0x79 0x02 0x03 0x03 0x79>;
				phandle = <0x1a>;
			};
		};

		i2c3-m0 {

			i2c3m0-xfer {
				rockchip,pins = <0x00 0x0f 0x02 0x79 0x00 0x10 0x02 0x79>;
				phandle = <0x1b>;
			};
		};

		i2c3-m1 {

			i2c3m1-xfer {
				rockchip,pins = <0x03 0x0c 0x02 0x79 0x03 0x0d 0x02 0x79>;
				phandle = <0xdc>;
			};
		};

		i2c3-m2 {

			i2c3m2-xfer {
				rockchip,pins = <0x02 0x01 0x03 0x79 0x02 0x00 0x03 0x79>;
				phandle = <0xdd>;
			};
		};

		i2s_2ch_0 {

			i2s-2ch-0-mclk {
				rockchip,pins = <0x04 0x0c 0x01 0x7a>;
				phandle = <0xde>;
			};

			i2s-2ch-0-sclk {
				rockchip,pins = <0x04 0x0d 0x01 0x7a>;
				phandle = <0x5b>;
			};

			i2s-2ch-0-lrck {
				rockchip,pins = <0x04 0x0e 0x01 0x7a>;
				phandle = <0x5c>;
			};

			i2s-2ch-0-sdo {
				rockchip,pins = <0x04 0x0f 0x01 0x7a>;
				phandle = <0x5e>;
			};

			i2s-2ch-0-sdi {
				rockchip,pins = <0x04 0x10 0x01 0x7a>;
				phandle = <0x5d>;
			};
		};

		i2s_8ch_0 {

			i2s-8ch-0-mclk {
				rockchip,pins = <0x02 0x04 0x01 0x7a>;
				phandle = <0x5a>;
			};

			i2s-8ch-0-sclktx {
				rockchip,pins = <0x02 0x05 0x01 0x7a>;
				phandle = <0x4e>;
			};

			i2s-8ch-0-sclkrx {
				rockchip,pins = <0x02 0x06 0x01 0x7a>;
				phandle = <0x4f>;
			};

			i2s-8ch-0-lrcktx {
				rockchip,pins = <0x02 0x07 0x01 0x7a>;
				phandle = <0x50>;
			};

			i2s-8ch-0-lrckrx {
				rockchip,pins = <0x02 0x08 0x01 0x7a>;
				phandle = <0x51>;
			};

			i2s-8ch-0-sdo0 {
				rockchip,pins = <0x02 0x09 0x01 0x7a>;
				phandle = <0x56>;
			};

			i2s-8ch-0-sdo1 {
				rockchip,pins = <0x02 0x0a 0x01 0x7a>;
				phandle = <0x57>;
			};

			i2s-8ch-0-sdo2 {
				rockchip,pins = <0x02 0x0b 0x01 0x7a>;
				phandle = <0x58>;
			};

			i2s-8ch-0-sdo3 {
				rockchip,pins = <0x02 0x0c 0x01 0x7a>;
				phandle = <0x59>;
			};

			i2s-8ch-0-sdi0 {
				rockchip,pins = <0x02 0x0d 0x01 0x7a>;
				phandle = <0x52>;
			};

			i2s-8ch-0-sdi1 {
				rockchip,pins = <0x02 0x0e 0x01 0x7a>;
				phandle = <0x53>;
			};

			i2s-8ch-0-sdi2 {
				rockchip,pins = <0x02 0x0f 0x01 0x7a>;
				phandle = <0x54>;
			};

			i2s-8ch-0-sdi3 {
				rockchip,pins = <0x02 0x10 0x01 0x7a>;
				phandle = <0x55>;
			};
		};

		i2s_8ch_1_m0 {

			i2s-8ch-1-m0-mclk {
				rockchip,pins = <0x01 0x02 0x02 0x7a>;
				phandle = <0xdf>;
			};

			i2s-8ch-1-m0-sclktx {
				rockchip,pins = <0x01 0x03 0x02 0x7a>;
				phandle = <0xe0>;
			};

			i2s-8ch-1-m0-sclkrx {
				rockchip,pins = <0x01 0x04 0x02 0x7a>;
				phandle = <0xe1>;
			};

			i2s-8ch-1-m0-lrcktx {
				rockchip,pins = <0x01 0x05 0x02 0x7a>;
				phandle = <0xe2>;
			};

			i2s-8ch-1-m0-lrckrx {
				rockchip,pins = <0x01 0x06 0x02 0x7a>;
				phandle = <0xe3>;
			};

			i2s-8ch-1-m0-sdo0 {
				rockchip,pins = <0x01 0x07 0x02 0x7a>;
				phandle = <0xe4>;
			};

			i2s-8ch-1-m0-sdo1-sdi3 {
				rockchip,pins = <0x01 0x08 0x02 0x7a>;
				phandle = <0xe5>;
			};

			i2s-8ch-1-m0-sdo2-sdi2 {
				rockchip,pins = <0x01 0x09 0x02 0x7a>;
				phandle = <0xe6>;
			};

			i2s-8ch-1-m0-sdo3_sdi1 {
				rockchip,pins = <0x01 0x0a 0x02 0x7a>;
				phandle = <0xe7>;
			};

			i2s-8ch-1-m0-sdi0 {
				rockchip,pins = <0x01 0x0b 0x02 0x7a>;
				phandle = <0xe8>;
			};
		};

		i2s_8ch_1_m1 {

			i2s-8ch-1-m1-mclk {
				rockchip,pins = <0x01 0x0c 0x02 0x7a>;
				phandle = <0xe9>;
			};

			i2s-8ch-1-m1-sclktx {
				rockchip,pins = <0x01 0x0d 0x02 0x7a>;
				phandle = <0xea>;
			};

			i2s-8ch-1-m1-sclkrx {
				rockchip,pins = <0x01 0x0e 0x02 0x7a>;
				phandle = <0xeb>;
			};

			i2s-8ch-1-m1-lrcktx {
				rockchip,pins = <0x01 0x0f 0x02 0x7a>;
				phandle = <0xec>;
			};

			i2s-8ch-1-m1-lrckrx {
				rockchip,pins = <0x01 0x10 0x02 0x7a>;
				phandle = <0xed>;
			};

			i2s-8ch-1-m1-sdo0 {
				rockchip,pins = <0x01 0x11 0x02 0x7a>;
				phandle = <0xee>;
			};

			i2s-8ch-1-m1-sdo1-sdi3 {
				rockchip,pins = <0x01 0x12 0x02 0x7a>;
				phandle = <0xef>;
			};

			i2s-8ch-1-m1-sdo2-sdi2 {
				rockchip,pins = <0x01 0x13 0x02 0x7a>;
				phandle = <0xf0>;
			};

			i2s-8ch-1-m1-sdo3_sdi1 {
				rockchip,pins = <0x01 0x14 0x02 0x7a>;
				phandle = <0xf1>;
			};

			i2s-8ch-1-m1-sdi0 {
				rockchip,pins = <0x01 0x15 0x02 0x7a>;
				phandle = <0xf2>;
			};
		};

		lcdc {

			lcdc-ctl {
				rockchip,pins = <0x01 0x00 0x01 0x7b 0x01 0x01 0x01 0x7b 0x01 0x02 0x01 0x7b 0x01 0x03 0x01 0x7b 0x01 0x04 0x01 0x7b 0x01 0x05 0x01 0x7b 0x01 0x06 0x01 0x7b 0x01 0x07 0x01 0x7b 0x01 0x08 0x01 0x7b 0x01 0x09 0x01 0x7b 0x01 0x0a 0x01 0x7b 0x01 0x0b 0x01 0x7b 0x01 0x0c 0x01 0x7b 0x01 0x0d 0x01 0x7b 0x01 0x0e 0x01 0x7b 0x01 0x0f 0x01 0x7b 0x01 0x10 0x01 0x7b 0x01 0x11 0x01 0x7b 0x01 0x12 0x01 0x7b 0x01 0x13 0x01 0x7b 0x01 0x14 0x01 0x7b 0x01 0x15 0x01 0x7b>;
				phandle = <0x12>;
			};

			lcdc-rgb888-m0 {
				rockchip,pins = <0x01 0x16 0x06 0x7b 0x01 0x17 0x06 0x7b 0x02 0x09 0x03 0x7b 0x02 0x0a 0x03 0x7b 0x02 0x0f 0x03 0x7b 0x02 0x10 0x03 0x7b>;
				phandle = <0xf3>;
			};

			lcdc-rgb888-m1 {
				rockchip,pins = <0x03 0x06 0x03 0x7b 0x03 0x07 0x03 0x7b 0x03 0x08 0x03 0x7b 0x03 0x09 0x03 0x7b 0x03 0x0a 0x04 0x7b 0x03 0x0b 0x04 0x7b>;
				phandle = <0xf4>;
			};
		};

		pdm_m0 {

			pdm-m0-clk {
				rockchip,pins = <0x01 0x04 0x03 0x7a>;
				phandle = <0xf5>;
			};

			pdm-m0-sdi0 {
				rockchip,pins = <0x01 0x0b 0x03 0x7a>;
				phandle = <0xf6>;
			};

			pdm-m0-sdi1 {
				rockchip,pins = <0x01 0x0a 0x03 0x7a>;
				phandle = <0xf7>;
			};

			pdm-m0-sdi2 {
				rockchip,pins = <0x01 0x09 0x03 0x7a>;
				phandle = <0xf8>;
			};

			pdm-m0-sdi3 {
				rockchip,pins = <0x01 0x08 0x03 0x7a>;
				phandle = <0xf9>;
			};
		};

		pdm_m1 {

			pdm-m1-clk {
				rockchip,pins = <0x01 0x0e 0x04 0x7a>;
				phandle = <0xfa>;
			};

			pdm-m1-sdi0 {
				rockchip,pins = <0x01 0x15 0x04 0x7a>;
				phandle = <0xfb>;
			};

			pdm-m1-sdi1 {
				rockchip,pins = <0x01 0x14 0x04 0x7a>;
				phandle = <0xfc>;
			};

			pdm-m1-sdi2 {
				rockchip,pins = <0x01 0x13 0x04 0x7a>;
				phandle = <0xfd>;
			};

			pdm-m1-sdi3 {
				rockchip,pins = <0x01 0x12 0x04 0x7a>;
				phandle = <0xfe>;
			};
		};

		pdm_m2 {

			pdm-m2-clkm {
				rockchip,pins = <0x02 0x04 0x03 0x7a>;
				phandle = <0xff>;
			};

			pdm-m2-clk {
				rockchip,pins = <0x02 0x06 0x02 0x7a>;
				phandle = <0x5f>;
			};

			pdm-m2-sdi0 {
				rockchip,pins = <0x02 0x0d 0x02 0x7a>;
				phandle = <0x60>;
			};

			pdm-m2-sdi1 {
				rockchip,pins = <0x02 0x0e 0x02 0x7a>;
				phandle = <0x61>;
			};

			pdm-m2-sdi2 {
				rockchip,pins = <0x02 0x0f 0x02 0x7a>;
				phandle = <0x62>;
			};

			pdm-m2-sdi3 {
				rockchip,pins = <0x02 0x10 0x02 0x7a>;
				phandle = <0x63>;
			};
		};

		spdif_in {

			spdif-in {
				rockchip,pins = <0x00 0x12 0x01 0x7a>;
				phandle = <0x65>;
			};
		};

		spdif_out {

			spdif-out {
				rockchip,pins = <0x00 0x11 0x01 0x7a>;
				phandle = <0x64>;
			};
		};

		tsadc {

			tsadc-otp-gpio {
				rockchip,pins = <0x00 0x0a 0x00 0x7a>;
				phandle = <0x4b>;
			};

			tsadc-otp-out {
				rockchip,pins = <0x00 0x0a 0x01 0x7a>;
				phandle = <0x4c>;
			};
		};

		uart0 {

			uart0-xfer {
				rockchip,pins = <0x02 0x01 0x01 0x7c 0x02 0x00 0x01 0x7c>;
				phandle = <0x1f>;
			};

			uart0-cts {
				rockchip,pins = <0x02 0x02 0x01 0x7a>;
				phandle = <0x100>;
			};

			uart0-rts {
				rockchip,pins = <0x02 0x03 0x01 0x7a>;
				phandle = <0x101>;
			};

			uart0-rts-gpio {
				rockchip,pins = <0x02 0x03 0x00 0x7a>;
				phandle = <0x102>;
			};
		};

		uart1 {

			uart1-xfer {
				rockchip,pins = <0x01 0x19 0x01 0x7c 0x01 0x18 0x01 0x7c>;
				phandle = <0x20>;
			};

			uart1-cts {
				rockchip,pins = <0x01 0x16 0x01 0x7a>;
				phandle = <0x103>;
			};

			uart1-rts {
				rockchip,pins = <0x01 0x17 0x01 0x7a>;
				phandle = <0x104>;
			};
		};

		uart2-m0 {

			uart2m0-xfer {
				rockchip,pins = <0x01 0x17 0x02 0x7c 0x01 0x16 0x02 0x7c>;
				phandle = <0x21>;
			};
		};

		uart2-m1 {

			uart2m1-xfer {
				rockchip,pins = <0x04 0x1b 0x02 0x7c 0x04 0x1a 0x02 0x7c>;
				phandle = <0x105>;
			};
		};

		uart3 {

			uart3-xfer {
				rockchip,pins = <0x03 0x0d 0x04 0x7c 0x03 0x0c 0x04 0x7c>;
				phandle = <0x22>;
			};
		};

		uart3-m1 {

			uart3m1-xfer {
				rockchip,pins = <0x00 0x12 0x03 0x7c 0x00 0x11 0x03 0x7c>;
				phandle = <0x106>;
			};
		};

		uart4 {

			uart4-xfer {
				rockchip,pins = <0x04 0x09 0x01 0x7c 0x04 0x08 0x01 0x7c>;
				phandle = <0x24>;
			};

			uart4-cts {
				rockchip,pins = <0x04 0x06 0x01 0x7a>;
				phandle = <0x25>;
			};

			uart4-rts {
				rockchip,pins = <0x04 0x07 0x01 0x7a>;
				phandle = <0x26>;
			};

			uart4-rts-gpio {
				rockchip,pins = <0x04 0x07 0x00 0x7a>;
				phandle = <0x107>;
			};
		};

		spi0 {

			spi0-clk {
				rockchip,pins = <0x02 0x02 0x02 0x7d>;
				phandle = <0x27>;
			};

			spi0-csn0 {
				rockchip,pins = <0x02 0x03 0x02 0x7d>;
				phandle = <0x28>;
			};

			spi0-miso {
				rockchip,pins = <0x02 0x00 0x02 0x7d>;
				phandle = <0x29>;
			};

			spi0-mosi {
				rockchip,pins = <0x02 0x01 0x02 0x7d>;
				phandle = <0x2a>;
			};

			spi0-clk-hs {
				rockchip,pins = <0x02 0x02 0x02 0x7e>;
				phandle = <0x2b>;
			};

			spi0-miso-hs {
				rockchip,pins = <0x02 0x00 0x02 0x7e>;
				phandle = <0x2c>;
			};

			spi0-mosi-hs {
				rockchip,pins = <0x02 0x01 0x02 0x7e>;
				phandle = <0x2d>;
			};
		};

		spi1 {

			spi1-clk {
				rockchip,pins = <0x03 0x0b 0x03 0x7d>;
				phandle = <0x2e>;
			};

			spi1-csn0 {
				rockchip,pins = <0x03 0x0d 0x03 0x7d>;
				phandle = <0x2f>;
			};

			spi1-miso {
				rockchip,pins = <0x03 0x0a 0x03 0x7d>;
				phandle = <0x30>;
			};

			spi1-mosi {
				rockchip,pins = <0x03 0x0c 0x03 0x7d>;
				phandle = <0x31>;
			};

			spi1-clk-hs {
				rockchip,pins = <0x03 0x0b 0x03 0x7e>;
				phandle = <0x32>;
			};

			spi1-miso-hs {
				rockchip,pins = <0x03 0x0a 0x03 0x7e>;
				phandle = <0x33>;
			};

			spi1-mosi-hs {
				rockchip,pins = <0x03 0x0c 0x03 0x7e>;
				phandle = <0x34>;
			};
		};

		spi1-m1 {

			spi1m1-miso {
				rockchip,pins = <0x02 0x04 0x02 0x7d>;
				phandle = <0x108>;
			};

			spi1m1-mosi {
				rockchip,pins = <0x02 0x05 0x02 0x7d>;
				phandle = <0x109>;
			};

			spi1m1-clk {
				rockchip,pins = <0x02 0x07 0x02 0x7d>;
				phandle = <0x10a>;
			};

			spi1m1-csn0 {
				rockchip,pins = <0x02 0x09 0x02 0x7d>;
				phandle = <0x10b>;
			};

			spi1m1-miso-hs {
				rockchip,pins = <0x02 0x04 0x02 0x7e>;
				phandle = <0x10c>;
			};

			spi1m1-mosi-hs {
				rockchip,pins = <0x02 0x05 0x02 0x7e>;
				phandle = <0x10d>;
			};

			spi1m1-clk-hs {
				rockchip,pins = <0x02 0x07 0x02 0x7e>;
				phandle = <0x10e>;
			};

			spi1m1-csn0-hs {
				rockchip,pins = <0x02 0x09 0x02 0x7e>;
				phandle = <0x10f>;
			};
		};

		spi2 {

			spi2-clk {
				rockchip,pins = <0x01 0x18 0x03 0x7d>;
				phandle = <0x35>;
			};

			spi2-csn0 {
				rockchip,pins = <0x01 0x19 0x03 0x7d>;
				phandle = <0x36>;
			};

			spi2-miso {
				rockchip,pins = <0x01 0x16 0x03 0x7d>;
				phandle = <0x37>;
			};

			spi2-mosi {
				rockchip,pins = <0x01 0x17 0x03 0x7d>;
				phandle = <0x38>;
			};

			spi2-clk-hs {
				rockchip,pins = <0x01 0x18 0x03 0x7e>;
				phandle = <0x39>;
			};

			spi2-miso-hs {
				rockchip,pins = <0x01 0x16 0x03 0x7e>;
				phandle = <0x3a>;
			};

			spi2-mosi-hs {
				rockchip,pins = <0x01 0x17 0x03 0x7e>;
				phandle = <0x3b>;
			};
		};

		sdmmc {

			sdmmc-clk {
				rockchip,pins = <0x04 0x1d 0x01 0x7b>;
				phandle = <0x69>;
			};

			sdmmc-cmd {
				rockchip,pins = <0x04 0x1c 0x01 0x7d>;
				phandle = <0x6a>;
			};

			sdmmc-det {
				rockchip,pins = <0x00 0x03 0x01 0x7d>;
				phandle = <0x6b>;
			};

			sdmmc-pwren {
				rockchip,pins = <0x04 0x1e 0x01 0x7b>;
				phandle = <0x110>;
			};

			sdmmc-bus1 {
				rockchip,pins = <0x04 0x18 0x01 0x7d>;
				phandle = <0x111>;
			};

			sdmmc-bus4 {
				rockchip,pins = <0x04 0x18 0x01 0x7d 0x04 0x19 0x01 0x7d 0x04 0x1a 0x01 0x7d 0x04 0x1b 0x01 0x7d>;
				phandle = <0x6c>;
			};

			sdmmc-gpio {
				rockchip,pins = <0x04 0x18 0x00 0x7d 0x04 0x19 0x00 0x7d 0x04 0x1a 0x00 0x7d 0x04 0x1b 0x00 0x7d 0x04 0x1c 0x00 0x7d 0x04 0x1d 0x00 0x7d 0x04 0x1e 0x00 0x7d>;
				phandle = <0x112>;
			};
		};

		sdio {

			sdio-clk {
				rockchip,pins = <0x04 0x05 0x01 0x7f>;
				phandle = <0x71>;
			};

			sdio-cmd {
				rockchip,pins = <0x04 0x04 0x01 0x7e>;
				phandle = <0x70>;
			};

			sdio-pwren {
				rockchip,pins = <0x00 0x02 0x01 0x7f>;
				phandle = <0x113>;
			};

			sdio-wrpt {
				rockchip,pins = <0x00 0x01 0x01 0x7f>;
				phandle = <0x114>;
			};

			sdio-intn {
				rockchip,pins = <0x00 0x00 0x01 0x7f>;
				phandle = <0x115>;
			};

			sdio-bus1 {
				rockchip,pins = <0x04 0x00 0x01 0x7e>;
				phandle = <0x116>;
			};

			sdio-bus4 {
				rockchip,pins = <0x04 0x00 0x01 0x7e 0x04 0x01 0x01 0x7e 0x04 0x02 0x01 0x7e 0x04 0x03 0x01 0x7e>;
				phandle = <0x6f>;
			};

			sdio-gpio {
				rockchip,pins = <0x04 0x00 0x00 0x7d 0x04 0x01 0x00 0x7d 0x04 0x02 0x00 0x7d 0x04 0x03 0x00 0x7d 0x04 0x04 0x00 0x7d 0x04 0x05 0x00 0x7d>;
				phandle = <0x117>;
			};
		};

		emmc {

			emmc-clk {
				rockchip,pins = <0x03 0x09 0x02 0x7f>;
				phandle = <0x118>;
			};

			emmc-cmd {
				rockchip,pins = <0x03 0x08 0x02 0x7e>;
				phandle = <0x119>;
			};

			emmc-pwren {
				rockchip,pins = <0x03 0x0b 0x02 0x7a>;
				phandle = <0x11a>;
			};

			emmc-rstn {
				rockchip,pins = <0x03 0x0a 0x02 0x7a>;
				phandle = <0x11b>;
			};

			emmc-bus1 {
				rockchip,pins = <0x03 0x00 0x02 0x7e>;
				phandle = <0x11c>;
			};

			emmc-bus4 {
				rockchip,pins = <0x03 0x00 0x02 0x7e 0x03 0x01 0x02 0x7e 0x03 0x02 0x02 0x7e 0x03 0x03 0x02 0x7e>;
				phandle = <0x11d>;
			};

			emmc-bus8 {
				rockchip,pins = <0x03 0x00 0x02 0x7e 0x03 0x01 0x02 0x7e 0x03 0x02 0x02 0x7e 0x03 0x03 0x02 0x7e 0x03 0x04 0x02 0x7e 0x03 0x05 0x02 0x7e 0x03 0x06 0x02 0x7e 0x03 0x07 0x02 0x7e>;
				phandle = <0x11e>;
			};
		};

		flash {

			flash-csn0 {
				rockchip,pins = <0x03 0x0d 0x01 0x7a>;
				phandle = <0x11f>;
			};

			flash-rdy {
				rockchip,pins = <0x03 0x0c 0x01 0x7a>;
				phandle = <0x120>;
			};

			flash-ale {
				rockchip,pins = <0x03 0x0b 0x01 0x7a>;
				phandle = <0x121>;
			};

			flash-cle {
				rockchip,pins = <0x03 0x09 0x01 0x7a>;
				phandle = <0x122>;
			};

			flash-wrn {
				rockchip,pins = <0x03 0x08 0x01 0x7a>;
				phandle = <0x123>;
			};

			flash-rdn {
				rockchip,pins = <0x03 0x0a 0x01 0x7a>;
				phandle = <0x124>;
			};

			flash-bus8 {
				rockchip,pins = <0x03 0x00 0x01 0x80 0x03 0x01 0x01 0x80 0x03 0x02 0x01 0x80 0x03 0x03 0x01 0x80 0x03 0x04 0x01 0x80 0x03 0x05 0x01 0x80 0x03 0x06 0x01 0x80 0x03 0x07 0x01 0x80>;
				phandle = <0x125>;
			};
		};

		pwm0 {

			pwm0-pin {
				rockchip,pins = <0x00 0x0d 0x01 0x7a>;
				phandle = <0x126>;
			};

			pwm0-pin-pull-down {
				rockchip,pins = <0x00 0x0d 0x01 0x78>;
				phandle = <0x44>;
			};
		};

		pwm1 {

			pwm1-pin {
				rockchip,pins = <0x00 0x0e 0x01 0x7a>;
				phandle = <0x45>;
			};

			pwm1-pin-pull-down {
				rockchip,pins = <0x00 0x0e 0x01 0x78>;
				phandle = <0x127>;
			};
		};

		pwm2 {

			pwm2-pin {
				rockchip,pins = <0x00 0x0f 0x01 0x7a>;
				phandle = <0x46>;
			};

			pwm2-pin-pull-down {
				rockchip,pins = <0x00 0x0f 0x01 0x78>;
				phandle = <0x128>;
			};
		};

		pwm3 {

			pwm3-pin {
				rockchip,pins = <0x00 0x10 0x01 0x7a>;
				phandle = <0x47>;
			};

			pwm3-pin-pull-down {
				rockchip,pins = <0x00 0x10 0x01 0x78>;
				phandle = <0x129>;
			};
		};

		pwm4 {

			pwm4-pin {
				rockchip,pins = <0x00 0x01 0x02 0x7a>;
				phandle = <0x40>;
			};

			pwm4-pin-pull-down {
				rockchip,pins = <0x00 0x01 0x02 0x78>;
				phandle = <0x12a>;
			};
		};

		pwm5 {

			pwm5-pin {
				rockchip,pins = <0x00 0x11 0x02 0x7a>;
				phandle = <0x41>;
			};

			pwm5-pin-pull-down {
				rockchip,pins = <0x00 0x11 0x02 0x78>;
				phandle = <0x12b>;
			};
		};

		pwm6 {

			pwm6-pin {
				rockchip,pins = <0x00 0x12 0x02 0x7a>;
				phandle = <0x42>;
			};

			pwm6-pin-pull-down {
				rockchip,pins = <0x00 0x12 0x02 0x78>;
				phandle = <0x12c>;
			};
		};

		pwm7 {

			pwm7-pin {
				rockchip,pins = <0x02 0x08 0x02 0x7a>;
				phandle = <0x43>;
			};

			pwm7-pin-pull-down {
				rockchip,pins = <0x02 0x08 0x02 0x78>;
				phandle = <0x12d>;
			};
		};

		pwm8 {

			pwm8-pin {
				rockchip,pins = <0x02 0x0a 0x02 0x7a>;
				phandle = <0x3c>;
			};

			pwm8-pin-pull-down {
				rockchip,pins = <0x02 0x0a 0x02 0x78>;
				phandle = <0x12e>;
			};
		};

		pwm9 {

			pwm9-pin {
				rockchip,pins = <0x02 0x0b 0x02 0x7a>;
				phandle = <0x3d>;
			};

			pwm9-pin-pull-down {
				rockchip,pins = <0x02 0x0b 0x02 0x78>;
				phandle = <0x12f>;
			};
		};

		pwm10 {

			pwm10-pin {
				rockchip,pins = <0x02 0x0c 0x02 0x7a>;
				phandle = <0x3e>;
			};

			pwm10-pin-pull-down {
				rockchip,pins = <0x02 0x0c 0x02 0x78>;
				phandle = <0x130>;
			};
		};

		pwm11 {

			pwm11-pin {
				rockchip,pins = <0x02 0x10 0x04 0x7a>;
				phandle = <0x3f>;
			};

			pwm11-pin-pull-down {
				rockchip,pins = <0x02 0x10 0x04 0x78>;
				phandle = <0x131>;
			};
		};

		gmac {

			rmii-pins {
				rockchip,pins = <0x01 0x11 0x03 0x81 0x01 0x13 0x03 0x81 0x01 0x12 0x03 0x81 0x01 0x14 0x03 0x7a 0x01 0x15 0x03 0x7a 0x01 0x0f 0x03 0x7a 0x01 0x10 0x03 0x7a 0x01 0x0e 0x03 0x7a 0x01 0x0d 0x03 0x7a>;
				phandle = <0x72>;
			};

			mac-refclk-12ma {
				rockchip,pins = <0x01 0x0c 0x03 0x81>;
				phandle = <0x73>;
			};

			mac-refclk {
				rockchip,pins = <0x01 0x0c 0x03 0x7a>;
				phandle = <0x132>;
			};
		};

		gmac-m1 {

			rmiim1-pins {
				rockchip,pins = <0x04 0x0f 0x02 0x81 0x04 0x05 0x02 0x81 0x04 0x04 0x02 0x81 0x04 0x02 0x02 0x7a 0x04 0x03 0x02 0x7a 0x04 0x00 0x02 0x7a 0x04 0x01 0x02 0x7a 0x04 0x0e 0x02 0x7a 0x04 0x0d 0x02 0x7a>;
				phandle = <0x133>;
			};

			macm1-refclk-12ma {
				rockchip,pins = <0x04 0x0c 0x02 0x81>;
				phandle = <0x134>;
			};

			macm1-refclk {
				rockchip,pins = <0x04 0x0c 0x02 0x7a>;
				phandle = <0x135>;
			};
		};

		rtc {

			rtc-32k {
				rockchip,pins = <0x00 0x13 0x01 0x7a>;
				phandle = <0x77>;
			};
		};

		can-m0 {

			canm0-pins {
				rockchip,pins = <0x00 0x0b 0x02 0x7a 0x00 0x0c 0x02 0x7a>;
				phandle = <0x136>;
			};
		};

		can-m1 {

			canm1-pins {
				rockchip,pins = <0x01 0x16 0x05 0x7a 0x01 0x17 0x05 0x7a>;
				phandle = <0x137>;
			};
		};

		can-m2 {

			canm2-pins {
				rockchip,pins = <0x02 0x02 0x04 0x7a 0x02 0x03 0x04 0x7a>;
				phandle = <0x138>;
			};
		};

		owire-m0 {

			owirem0-pins {
				rockchip,pins = <0x00 0x0b 0x03 0x7a>;
				phandle = <0x139>;
			};
		};

		owire-m1 {

			owirem1-pins {
				rockchip,pins = <0x01 0x16 0x07 0x7a>;
				phandle = <0x13a>;
			};
		};

		owire-m2 {

			owirem2-pins {
				rockchip,pins = <0x02 0x02 0x05 0x7a>;
				phandle = <0x13b>;
			};
		};

		usb {

			otg-vbus-drv {
				rockchip,pins = <0x00 0x15 0x00 0x7a>;
				phandle = <0x84>;
			};
		};

		rtc-hym8563 {

			hym8563-int {
				rockchip,pins = <0x00 0x11 0x00 0x7c>;
				phandle = <0x18>;
			};
		};

		pps-pins {

			pps-pins {
				rockchip,pins = <0x02 0x0e 0x00 0x7a>;
				phandle = <0x86>;
			};
		};
	};

	dummy-codec {
		compatible = "rockchip,dummy-codec";
		#sound-dai-cells = <0x00>;
		phandle = <0x13c>;
	};

	vdd-core {
		compatible = "pwm-regulator";
		pwms = <0x82 0x00 0x1388 0x01>;
		regulator-name = "vdd_core";
		regulator-min-microvolt = <0xc9e78>;
		regulator-max-microvolt = <0x147260>;
		regulator-init-microvolt = <0xf7cd8>;
		regulator-always-on;
		regulator-boot-on;
		regulator-settling-time-up-us = <0xfa>;
		status = "okay";
		phandle = <0x06>;
	};

	vdd-log {
		compatible = "regulator-fixed";
		regulator-name = "vdd_log";
		regulator-always-on;
		regulator-boot-on;
		regulator-min-microvolt = <0x100590>;
		regulator-max-microvolt = <0x100590>;
		phandle = <0x13d>;
	};

	vdd-1v0 {
		compatible = "regulator-fixed";
		regulator-name = "vdd_1v0";
		regulator-always-on;
		regulator-boot-on;
		regulator-min-microvolt = <0xf4240>;
		regulator-max-microvolt = <0xf4240>;
		phandle = <0x13e>;
	};

	vcc-1v8 {
		compatible = "regulator-fixed";
		regulator-name = "vcc_1v8";
		regulator-always-on;
		regulator-boot-on;
		regulator-min-microvolt = <0x1b7740>;
		regulator-max-microvolt = <0x1b7740>;
		vin-supply = <0x13>;
		phandle = <0x14>;
	};

	vccio-sd {
		compatible = "regulator-gpio";
		regulator-name = "vccio_sd";
		regulator-min-microvolt = <0x1b7740>;
		regulator-max-microvolt = <0x325aa0>;
		states = <0x1b7740 0x00 0x325aa0 0x01>;
		phandle = <0x6e>;
	};

	vcc-sd {
		compatible = "regulator-fixed";
		gpio = <0x83 0x1e 0x01>;
		regulator-name = "vcc_sd";
		regulator-min-microvolt = <0x325aa0>;
		regulator-max-microvolt = <0x325aa0>;
		phandle = <0x6d>;
	};

	vcc-1v8-codec {
		compatible = "regulator-fixed";
		regulator-name = "vcc_1v8_codec";
		regulator-always-on;
		regulator-boot-on;
		regulator-min-microvolt = <0x1b7740>;
		regulator-max-microvolt = <0x1b7740>;
		vin-supply = <0x13>;
		phandle = <0x13f>;
	};

	vcc-ddr {
		compatible = "regulator-fixed";
		regulator-name = "vcc_ddr";
		regulator-always-on;
		regulator-boot-on;
		regulator-min-microvolt = <0x16e360>;
		regulator-max-microvolt = <0x16e360>;
		phandle = <0x140>;
	};

	vcc-io {
		compatible = "regulator-fixed";
		regulator-name = "vcc_io";
		regulator-always-on;
		regulator-boot-on;
		regulator-min-microvolt = <0x325aa0>;
		regulator-max-microvolt = <0x325aa0>;
		phandle = <0x13>;
	};

	vccio-flash {
		compatible = "regulator-fixed";
		regulator-name = "vccio_flash";
		regulator-always-on;
		regulator-boot-on;
		regulator-min-microvolt = <0x1b7740>;
		regulator-max-microvolt = <0x1b7740>;
		phandle = <0x15>;
	};

	vcc-phy-regulator {
		compatible = "regulator-fixed";
		regulator-name = "vcc_phy";
		regulator-always-on;
		regulator-boot-on;
		phandle = <0x74>;
	};

	otg-vbus-regulator {
		compatible = "regulator-fixed";
		enable-active-high;
		gpio = <0x19 0x15 0x00>;
		pinctrl-names = "default";
		pinctrl-0 = <0x84>;
		regulator-name = "vcc_otg_vbus";
		phandle = <0x1d>;
	};

	gpio_export {
		compatible = "gpio-export";
		#size-cells = <0x00>;

		FP_BUTTON_1 {
			gpio-export,name = "fp-button-1";
			gpios = <0x85 0x09 0x00>;
		};

		HDR_PPSOUT_EN {
			gpio-export,name = "hdr-ppsout-en";
			gpio-export,output = <0x00>;
			gpios = <0x85 0x04 0x00>;
		};

		BARREL_MECH {
			gpio-export,name = "barrel-mech";
			gpios = <0x19 0x0f 0x00>;
		};

		GPS_NRESET {
			gpio-export,name = "gps-nreset";
			gpio-export,output = <0x01>;
			gpios = <0x85 0x0f 0x00>;
		};

		GPS_RESET {
			gpio-export,name = "gps-reset";
			gpio-export,output = <0x00>;
			gpios = <0x85 0x10 0x00>;
		};

		POE_SENSE {
			gpio-export,name = "poe-sense";
			gpios = <0x85 0x0a 0x00>;
		};
	};

	gpio-leds {
		compatible = "gpio-leds";
		status = "okay";

		green-led {
			label = "green:power";
			gpios = <0x19 0x06 0x00>;
			linux,default-trigger = "heartbeat";
			default-state = "on";
		};

		blue-led {
			label = "blue:sd";
			gpios = <0x19 0x05 0x00>;
			linux,default-trigger = "mmc0";
			default-state = "off";
		};

		led-system {
			label = "green:system";
			gpios = <0x85 0x07 0x00>;
			linux,default-trigger = "timer";
			default-state = "off";
		};

		led-sd {
			label = "green:sd";
			gpios = <0x85 0x05 0x00>;
			linux,default-trigger = "mmc0";
			default-state = "off";
		};

		led-ntp {
			label = "green:ntp";
			gpios = <0x85 0x0d 0x00>;
			linux,default-trigger = "none";
			default-state = "off";
		};
	};

	pps {
		compatible = "pps-gpio";
		pinctrl-names = "default";
		pinctrl-0 = <0x86>;
		gpios = <0x85 0x0e 0x00>;
		status = "okay";
		phandle = <0x141>;
	};

	__symbols__ {
		cpu0 = "/cpus/cpu@0";
		cpu1 = "/cpus/cpu@1";
		cpu2 = "/cpus/cpu@2";
		cpu3 = "/cpus/cpu@3";
		CPU_SLEEP = "/cpus/idle-states/cpu-sleep";
		l2 = "/cpus/l2-cache";
		cpu0_opp_table = "/cpu0-opp-table";
		display_subsystem = "/display-subsystem";
		route_rgb = "/display-subsystem/route/route-rgb";
		dmc = "/dmc";
		dmc_opp_table = "/dmc-opp-table";
		fiq_debugger = "/fiq-debugger";
		mac_clkin = "/external-mac-clock";
		ramoops_mem = "/ramoops_mem";
		ramoops = "/ramoops";
		rgb = "/rgb";
		rgb_in_vop = "/rgb/ports/port@0/endpoint@0";
		drm_logo = "/reserved-memory/drm-logo@00000000";
		rockchip_suspend = "/rockchip-suspend";
		xin24m = "/xin24m";
		grf = "/grf@ff000000";
		io_domains = "/grf@ff000000/io-domains";
		pmu_pvtm = "/grf@ff000000/pmu-pvtm";
		detect_grf = "/syscon@ff00b000";
		core_grf = "/syscon@ff00c000";
		pvtm = "/syscon@ff00c000/pvtm";
		i2c0 = "/i2c@ff040000";
		i2c1 = "/i2c@ff050000";
		hym8563 = "/i2c@ff050000/hym8563@51";
		eeprom54 = "/i2c@ff050000/eeprom@54";
		i2c2 = "/i2c@ff060000";
		i2c3 = "/i2c@ff070000";
		usb2phy_grf = "/syscon@ff008000";
		u2phy = "/syscon@ff008000/usb2-phy@100";
		u2phy_otg = "/syscon@ff008000/usb2-phy@100/otg-port";
		u2phy_host = "/syscon@ff008000/usb2-phy@100/host-port";
		wdt = "/watchdog@ff080000";
		uart0 = "/serial@ff0a0000";
		uart1 = "/serial@ff0b0000";
		uart2 = "/serial@ff0c0000";
		uart3 = "/serial@ff0d0000";
		uart4 = "/serial@ff0e0000";
		spi0 = "/spi@ff120000";
		spi1 = "/spi@ff130000";
		spi2 = "/spi@ff140000";
		pwm8 = "/pwm@ff160000";
		pwm9 = "/pwm@ff160010";
		pwm10 = "/pwm@ff160020";
		pwm11 = "/pwm@ff160030";
		pwm4 = "/pwm@ff170000";
		pwm5 = "/pwm@ff170010";
		pwm6 = "/pwm@ff170020";
		pwm7 = "/pwm@ff170030";
		pwm0 = "/pwm@ff180000";
		pwm1 = "/pwm@ff180010";
		pwm2 = "/pwm@ff180020";
		pwm3 = "/pwm@ff180030";
		rktimer = "/rktimer@ff1a0000";
		rk_timer_rtc = "/rk-timer-rtc@ff1a0020";
		saradc = "/saradc@ff1e0000";
		thermal_zones = "/thermal-zones";
		soc_thermal = "/thermal-zones/soc-thermal";
		threshold = "/thermal-zones/soc-thermal/trips/trip-point-0";
		target = "/thermal-zones/soc-thermal/trips/trip-point-1";
		soc_crit = "/thermal-zones/soc-thermal/trips/soc-crit";
		logic_thermal = "/thermal-zones/logic-thermal";
		tsadc = "/tsadc@ff1f0000";
		otp = "/otp@ff210000";
		otp_id = "/otp@ff210000/id@7";
		cpu_leakage = "/otp@ff210000/cpu-leakage@17";
		logic_leakage = "/otp@ff210000/logic-leakage@18";
		dmac0 = "/amba/dma-controller@ff2c0000";
		dmac1 = "/amba/dma-controller@ff2d0000";
		vop = "/vop@ff2e0000";
		vop_out = "/vop@ff2e0000/port";
		vop_out_rgb = "/vop@ff2e0000/port/endpoint@0";
		rng = "/rng@ff2f0000";
		i2s_8ch_0 = "/i2s@ff300000";
		i2s_8ch_1 = "/i2s@ff310000";
		i2s_8ch_2 = "/i2s@ff320000";
		i2s_8ch_3 = "/i2s@ff330000";
		i2s_2ch_0 = "/i2s@ff350000";
		i2s_2ch_1 = "/i2s@ff360000";
		pdm_8ch = "/pdm@ff380000";
		spdif_tx = "/spdif-tx@ff3a0000";
		spdif_rx = "/spdif-rx@ff3b0000";
		vad = "/vad@ff3c0000";
		usb20_otg = "/usb@ff400000";
		usb_host0_ehci = "/usb@ff440000";
		usb_host0_ohci = "/usb@ff450000";
		sdmmc = "/dwmmc@ff480000";
		emmc = "/dwmmc@ff490000";
		sdio = "/dwmmc@ff4a0000";
		nandc = "/nandc@ff4b0000";
		sfc = "/sfc@ff4c0000";
		mac = "/ethernet@ff4e0000";
		cru = "/clock-controller@ff500000";
		cpu_boost = "/cpu-boost@ff550000";
		acodec = "/acodec@ff560000";
		gic = "/interrupt-controller@ff580000";
		sram = "/sram@fff80000";
		vad_sram = "/sram@fff80000/vad-sram@8000";
		rockchip_system_monitor = "/rockchip-system-monitor";
		pinctrl = "/pinctrl";
		gpio0 = "/pinctrl/gpio0@ff220000";
		gpio1 = "/pinctrl/gpio1@ff230000";
		gpio2 = "/pinctrl/gpio2@ff240000";
		gpio3 = "/pinctrl/gpio3@ff250000";
		gpio4 = "/pinctrl/gpio4@ff260000";
		pcfg_pull_up = "/pinctrl/pcfg-pull-up";
		pcfg_pull_down = "/pinctrl/pcfg-pull-down";
		pcfg_pull_none = "/pinctrl/pcfg-pull-none";
		pcfg_pull_none_2ma = "/pinctrl/pcfg-pull-none-2ma";
		pcfg_pull_up_2ma = "/pinctrl/pcfg-pull-up-2ma";
		pcfg_pull_up_4ma = "/pinctrl/pcfg-pull-up-4ma";
		pcfg_pull_none_4ma = "/pinctrl/pcfg-pull-none-4ma";
		pcfg_pull_down_4ma = "/pinctrl/pcfg-pull-down-4ma";
		pcfg_pull_none_8ma = "/pinctrl/pcfg-pull-none-8ma";
		pcfg_pull_up_8ma = "/pinctrl/pcfg-pull-up-8ma";
		pcfg_pull_none_12ma = "/pinctrl/pcfg-pull-none-12ma";
		pcfg_pull_up_12ma = "/pinctrl/pcfg-pull-up-12ma";
		pcfg_pull_none_smt = "/pinctrl/pcfg-pull-none-smt";
		pcfg_output_high = "/pinctrl/pcfg-output-high";
		pcfg_output_low = "/pinctrl/pcfg-output-low";
		pcfg_input_high = "/pinctrl/pcfg-input-high";
		pcfg_input = "/pinctrl/pcfg-input";
		ext_micbias_en = "/pinctrl/ext_micbias/ext-micbias-en";
		i2c0_xfer = "/pinctrl/i2c0/i2c0-xfer";
		i2c1_xfer = "/pinctrl/i2c1/i2c1-xfer";
		i2c2_xfer = "/pinctrl/i2c2/i2c2-xfer";
		i2c3m0_xfer = "/pinctrl/i2c3-m0/i2c3m0-xfer";
		i2c3m1_xfer = "/pinctrl/i2c3-m1/i2c3m1-xfer";
		i2c3m2_xfer = "/pinctrl/i2c3-m2/i2c3m2-xfer";
		i2s_2ch_0_mclk = "/pinctrl/i2s_2ch_0/i2s-2ch-0-mclk";
		i2s_2ch_0_sclk = "/pinctrl/i2s_2ch_0/i2s-2ch-0-sclk";
		i2s_2ch_0_lrck = "/pinctrl/i2s_2ch_0/i2s-2ch-0-lrck";
		i2s_2ch_0_sdo = "/pinctrl/i2s_2ch_0/i2s-2ch-0-sdo";
		i2s_2ch_0_sdi = "/pinctrl/i2s_2ch_0/i2s-2ch-0-sdi";
		i2s_8ch_0_mclk = "/pinctrl/i2s_8ch_0/i2s-8ch-0-mclk";
		i2s_8ch_0_sclktx = "/pinctrl/i2s_8ch_0/i2s-8ch-0-sclktx";
		i2s_8ch_0_sclkrx = "/pinctrl/i2s_8ch_0/i2s-8ch-0-sclkrx";
		i2s_8ch_0_lrcktx = "/pinctrl/i2s_8ch_0/i2s-8ch-0-lrcktx";
		i2s_8ch_0_lrckrx = "/pinctrl/i2s_8ch_0/i2s-8ch-0-lrckrx";
		i2s_8ch_0_sdo0 = "/pinctrl/i2s_8ch_0/i2s-8ch-0-sdo0";
		i2s_8ch_0_sdo1 = "/pinctrl/i2s_8ch_0/i2s-8ch-0-sdo1";
		i2s_8ch_0_sdo2 = "/pinctrl/i2s_8ch_0/i2s-8ch-0-sdo2";
		i2s_8ch_0_sdo3 = "/pinctrl/i2s_8ch_0/i2s-8ch-0-sdo3";
		i2s_8ch_0_sdi0 = "/pinctrl/i2s_8ch_0/i2s-8ch-0-sdi0";
		i2s_8ch_0_sdi1 = "/pinctrl/i2s_8ch_0/i2s-8ch-0-sdi1";
		i2s_8ch_0_sdi2 = "/pinctrl/i2s_8ch_0/i2s-8ch-0-sdi2";
		i2s_8ch_0_sdi3 = "/pinctrl/i2s_8ch_0/i2s-8ch-0-sdi3";
		i2s_8ch_1_m0_mclk = "/pinctrl/i2s_8ch_1_m0/i2s-8ch-1-m0-mclk";
		i2s_8ch_1_m0_sclktx = "/pinctrl/i2s_8ch_1_m0/i2s-8ch-1-m0-sclktx";
		i2s_8ch_1_m0_sclkrx = "/pinctrl/i2s_8ch_1_m0/i2s-8ch-1-m0-sclkrx";
		i2s_8ch_1_m0_lrcktx = "/pinctrl/i2s_8ch_1_m0/i2s-8ch-1-m0-lrcktx";
		i2s_8ch_1_m0_lrckrx = "/pinctrl/i2s_8ch_1_m0/i2s-8ch-1-m0-lrckrx";
		i2s_8ch_1_m0_sdo0 = "/pinctrl/i2s_8ch_1_m0/i2s-8ch-1-m0-sdo0";
		i2s_8ch_1_m0_sdo1_sdi3 = "/pinctrl/i2s_8ch_1_m0/i2s-8ch-1-m0-sdo1-sdi3";
		i2s_8ch_1_m0_sdo2_sdi2 = "/pinctrl/i2s_8ch_1_m0/i2s-8ch-1-m0-sdo2-sdi2";
		i2s_8ch_1_m0_sdo3_sdi1 = "/pinctrl/i2s_8ch_1_m0/i2s-8ch-1-m0-sdo3_sdi1";
		i2s_8ch_1_m0_sdi0 = "/pinctrl/i2s_8ch_1_m0/i2s-8ch-1-m0-sdi0";
		i2s_8ch_1_m1_mclk = "/pinctrl/i2s_8ch_1_m1/i2s-8ch-1-m1-mclk";
		i2s_8ch_1_m1_sclktx = "/pinctrl/i2s_8ch_1_m1/i2s-8ch-1-m1-sclktx";
		i2s_8ch_1_m1_sclkrx = "/pinctrl/i2s_8ch_1_m1/i2s-8ch-1-m1-sclkrx";
		i2s_8ch_1_m1_lrcktx = "/pinctrl/i2s_8ch_1_m1/i2s-8ch-1-m1-lrcktx";
		i2s_8ch_1_m1_lrckrx = "/pinctrl/i2s_8ch_1_m1/i2s-8ch-1-m1-lrckrx";
		i2s_8ch_1_m1_sdo0 = "/pinctrl/i2s_8ch_1_m1/i2s-8ch-1-m1-sdo0";
		i2s_8ch_1_m1_sdo1_sdi3 = "/pinctrl/i2s_8ch_1_m1/i2s-8ch-1-m1-sdo1-sdi3";
		i2s_8ch_1_m1_sdo2_sdi2 = "/pinctrl/i2s_8ch_1_m1/i2s-8ch-1-m1-sdo2-sdi2";
		i2s_8ch_1_m1_sdo3_sdi1 = "/pinctrl/i2s_8ch_1_m1/i2s-8ch-1-m1-sdo3_sdi1";
		i2s_8ch_1_m1_sdi0 = "/pinctrl/i2s_8ch_1_m1/i2s-8ch-1-m1-sdi0";
		lcdc_ctl = "/pinctrl/lcdc/lcdc-ctl";
		lcdc_rgb888_m0 = "/pinctrl/lcdc/lcdc-rgb888-m0";
		lcdc_rgb888_m1 = "/pinctrl/lcdc/lcdc-rgb888-m1";
		pdm_m0_clk = "/pinctrl/pdm_m0/pdm-m0-clk";
		pdm_m0_sdi0 = "/pinctrl/pdm_m0/pdm-m0-sdi0";
		pdm_m0_sdi1 = "/pinctrl/pdm_m0/pdm-m0-sdi1";
		pdm_m0_sdi2 = "/pinctrl/pdm_m0/pdm-m0-sdi2";
		pdm_m0_sdi3 = "/pinctrl/pdm_m0/pdm-m0-sdi3";
		pdm_m1_clk = "/pinctrl/pdm_m1/pdm-m1-clk";
		pdm_m1_sdi0 = "/pinctrl/pdm_m1/pdm-m1-sdi0";
		pdm_m1_sdi1 = "/pinctrl/pdm_m1/pdm-m1-sdi1";
		pdm_m1_sdi2 = "/pinctrl/pdm_m1/pdm-m1-sdi2";
		pdm_m1_sdi3 = "/pinctrl/pdm_m1/pdm-m1-sdi3";
		pdm_m2_clkm = "/pinctrl/pdm_m2/pdm-m2-clkm";
		pdm_m2_clk = "/pinctrl/pdm_m2/pdm-m2-clk";
		pdm_m2_sdi0 = "/pinctrl/pdm_m2/pdm-m2-sdi0";
		pdm_m2_sdi1 = "/pinctrl/pdm_m2/pdm-m2-sdi1";
		pdm_m2_sdi2 = "/pinctrl/pdm_m2/pdm-m2-sdi2";
		pdm_m2_sdi3 = "/pinctrl/pdm_m2/pdm-m2-sdi3";
		spdif_in = "/pinctrl/spdif_in/spdif-in";
		spdif_out = "/pinctrl/spdif_out/spdif-out";
		tsadc_otp_gpio = "/pinctrl/tsadc/tsadc-otp-gpio";
		tsadc_otp_out = "/pinctrl/tsadc/tsadc-otp-out";
		uart0_xfer = "/pinctrl/uart0/uart0-xfer";
		uart0_cts = "/pinctrl/uart0/uart0-cts";
		uart0_rts = "/pinctrl/uart0/uart0-rts";
		uart0_rts_gpio = "/pinctrl/uart0/uart0-rts-gpio";
		uart1_xfer = "/pinctrl/uart1/uart1-xfer";
		uart1_cts = "/pinctrl/uart1/uart1-cts";
		uart1_rts = "/pinctrl/uart1/uart1-rts";
		uart2m0_xfer = "/pinctrl/uart2-m0/uart2m0-xfer";
		uart2m1_xfer = "/pinctrl/uart2-m1/uart2m1-xfer";
		uart3_xfer = "/pinctrl/uart3/uart3-xfer";
		uart3m1_xfer = "/pinctrl/uart3-m1/uart3m1-xfer";
		uart4_xfer = "/pinctrl/uart4/uart4-xfer";
		uart4_cts = "/pinctrl/uart4/uart4-cts";
		uart4_rts = "/pinctrl/uart4/uart4-rts";
		uart4_rts_gpio = "/pinctrl/uart4/uart4-rts-gpio";
		spi0_clk = "/pinctrl/spi0/spi0-clk";
		spi0_csn0 = "/pinctrl/spi0/spi0-csn0";
		spi0_miso = "/pinctrl/spi0/spi0-miso";
		spi0_mosi = "/pinctrl/spi0/spi0-mosi";
		spi0_clk_hs = "/pinctrl/spi0/spi0-clk-hs";
		spi0_miso_hs = "/pinctrl/spi0/spi0-miso-hs";
		spi0_mosi_hs = "/pinctrl/spi0/spi0-mosi-hs";
		spi1_clk = "/pinctrl/spi1/spi1-clk";
		spi1_csn0 = "/pinctrl/spi1/spi1-csn0";
		spi1_miso = "/pinctrl/spi1/spi1-miso";
		spi1_mosi = "/pinctrl/spi1/spi1-mosi";
		spi1_clk_hs = "/pinctrl/spi1/spi1-clk-hs";
		spi1_miso_hs = "/pinctrl/spi1/spi1-miso-hs";
		spi1_mosi_hs = "/pinctrl/spi1/spi1-mosi-hs";
		spi1m1_miso = "/pinctrl/spi1-m1/spi1m1-miso";
		spi1m1_mosi = "/pinctrl/spi1-m1/spi1m1-mosi";
		spi1m1_clk = "/pinctrl/spi1-m1/spi1m1-clk";
		spi1m1_csn0 = "/pinctrl/spi1-m1/spi1m1-csn0";
		spi1m1_miso_hs = "/pinctrl/spi1-m1/spi1m1-miso-hs";
		spi1m1_mosi_hs = "/pinctrl/spi1-m1/spi1m1-mosi-hs";
		spi1m1_clk_hs = "/pinctrl/spi1-m1/spi1m1-clk-hs";
		spi1m1_csn0_hs = "/pinctrl/spi1-m1/spi1m1-csn0-hs";
		spi2_clk = "/pinctrl/spi2/spi2-clk";
		spi2_csn0 = "/pinctrl/spi2/spi2-csn0";
		spi2_miso = "/pinctrl/spi2/spi2-miso";
		spi2_mosi = "/pinctrl/spi2/spi2-mosi";
		spi2_clk_hs = "/pinctrl/spi2/spi2-clk-hs";
		spi2_miso_hs = "/pinctrl/spi2/spi2-miso-hs";
		spi2_mosi_hs = "/pinctrl/spi2/spi2-mosi-hs";
		sdmmc_clk = "/pinctrl/sdmmc/sdmmc-clk";
		sdmmc_cmd = "/pinctrl/sdmmc/sdmmc-cmd";
		sdmmc_det = "/pinctrl/sdmmc/sdmmc-det";
		sdmmc_pwren = "/pinctrl/sdmmc/sdmmc-pwren";
		sdmmc_bus1 = "/pinctrl/sdmmc/sdmmc-bus1";
		sdmmc_bus4 = "/pinctrl/sdmmc/sdmmc-bus4";
		sdmmc_gpio = "/pinctrl/sdmmc/sdmmc-gpio";
		sdio_clk = "/pinctrl/sdio/sdio-clk";
		sdio_cmd = "/pinctrl/sdio/sdio-cmd";
		sdio_pwren = "/pinctrl/sdio/sdio-pwren";
		sdio_wrpt = "/pinctrl/sdio/sdio-wrpt";
		sdio_intn = "/pinctrl/sdio/sdio-intn";
		sdio_bus1 = "/pinctrl/sdio/sdio-bus1";
		sdio_bus4 = "/pinctrl/sdio/sdio-bus4";
		sdio_gpio = "/pinctrl/sdio/sdio-gpio";
		emmc_clk = "/pinctrl/emmc/emmc-clk";
		emmc_cmd = "/pinctrl/emmc/emmc-cmd";
		emmc_pwren = "/pinctrl/emmc/emmc-pwren";
		emmc_rstn = "/pinctrl/emmc/emmc-rstn";
		emmc_bus1 = "/pinctrl/emmc/emmc-bus1";
		emmc_bus4 = "/pinctrl/emmc/emmc-bus4";
		emmc_bus8 = "/pinctrl/emmc/emmc-bus8";
		flash_csn0 = "/pinctrl/flash/flash-csn0";
		flash_rdy = "/pinctrl/flash/flash-rdy";
		flash_ale = "/pinctrl/flash/flash-ale";
		flash_cle = "/pinctrl/flash/flash-cle";
		flash_wrn = "/pinctrl/flash/flash-wrn";
		flash_rdn = "/pinctrl/flash/flash-rdn";
		flash_bus8 = "/pinctrl/flash/flash-bus8";
		pwm0_pin = "/pinctrl/pwm0/pwm0-pin";
		pwm0_pin_pull_down = "/pinctrl/pwm0/pwm0-pin-pull-down";
		pwm1_pin = "/pinctrl/pwm1/pwm1-pin";
		pwm1_pin_pull_down = "/pinctrl/pwm1/pwm1-pin-pull-down";
		pwm2_pin = "/pinctrl/pwm2/pwm2-pin";
		pwm2_pin_pull_down = "/pinctrl/pwm2/pwm2-pin-pull-down";
		pwm3_pin = "/pinctrl/pwm3/pwm3-pin";
		pwm3_pin_pull_down = "/pinctrl/pwm3/pwm3-pin-pull-down";
		pwm4_pin = "/pinctrl/pwm4/pwm4-pin";
		pwm4_pin_pull_down = "/pinctrl/pwm4/pwm4-pin-pull-down";
		pwm5_pin = "/pinctrl/pwm5/pwm5-pin";
		pwm5_pin_pull_down = "/pinctrl/pwm5/pwm5-pin-pull-down";
		pwm6_pin = "/pinctrl/pwm6/pwm6-pin";
		pwm6_pin_pull_down = "/pinctrl/pwm6/pwm6-pin-pull-down";
		pwm7_pin = "/pinctrl/pwm7/pwm7-pin";
		pwm7_pin_pull_down = "/pinctrl/pwm7/pwm7-pin-pull-down";
		pwm8_pin = "/pinctrl/pwm8/pwm8-pin";
		pwm8_pin_pull_down = "/pinctrl/pwm8/pwm8-pin-pull-down";
		pwm9_pin = "/pinctrl/pwm9/pwm9-pin";
		pwm9_pin_pull_down = "/pinctrl/pwm9/pwm9-pin-pull-down";
		pwm10_pin = "/pinctrl/pwm10/pwm10-pin";
		pwm10_pin_pull_down = "/pinctrl/pwm10/pwm10-pin-pull-down";
		pwm11_pin = "/pinctrl/pwm11/pwm11-pin";
		pwm11_pin_pull_down = "/pinctrl/pwm11/pwm11-pin-pull-down";
		rmii_pins = "/pinctrl/gmac/rmii-pins";
		mac_refclk_12ma = "/pinctrl/gmac/mac-refclk-12ma";
		mac_refclk = "/pinctrl/gmac/mac-refclk";
		rmiim1_pins = "/pinctrl/gmac-m1/rmiim1-pins";
		macm1_refclk_12ma = "/pinctrl/gmac-m1/macm1-refclk-12ma";
		macm1_refclk = "/pinctrl/gmac-m1/macm1-refclk";
		rtc_32k = "/pinctrl/rtc/rtc-32k";
		canm0_pins = "/pinctrl/can-m0/canm0-pins";
		canm1_pins = "/pinctrl/can-m1/canm1-pins";
		canm2_pins = "/pinctrl/can-m2/canm2-pins";
		owirem0_pins = "/pinctrl/owire-m0/owirem0-pins";
		owirem1_pins = "/pinctrl/owire-m1/owirem1-pins";
		owirem2_pins = "/pinctrl/owire-m2/owirem2-pins";
		otg_vbus_drv = "/pinctrl/usb/otg-vbus-drv";
		hym8563_int = "/pinctrl/rtc-hym8563/hym8563-int";
		pps_pins = "/pinctrl/pps-pins/pps-pins";
		dummy_codec = "/dummy-codec";
		vdd_core = "/vdd-core";
		vdd_log = "/vdd-log";
		vdd_1v0 = "/vdd-1v0";
		vccio_sdio = "/vcc-1v8";
		vcc_1v8 = "/vcc-1v8";
		vccio_sd = "/vccio-sd";
		vcc_sd = "/vcc-sd";
		vcc_1v8_codec = "/vcc-1v8-codec";
		vcc_ddr = "/vcc-ddr";
		vcc_3v3_codec = "/vcc-io";
		vcc_io = "/vcc-io";
		vccio_flash = "/vccio-flash";
		vcc_phy = "/vcc-phy-regulator";
		vcc_otg_vbus = "/otg-vbus-regulator";
		pps = "/pps";
	};
};
